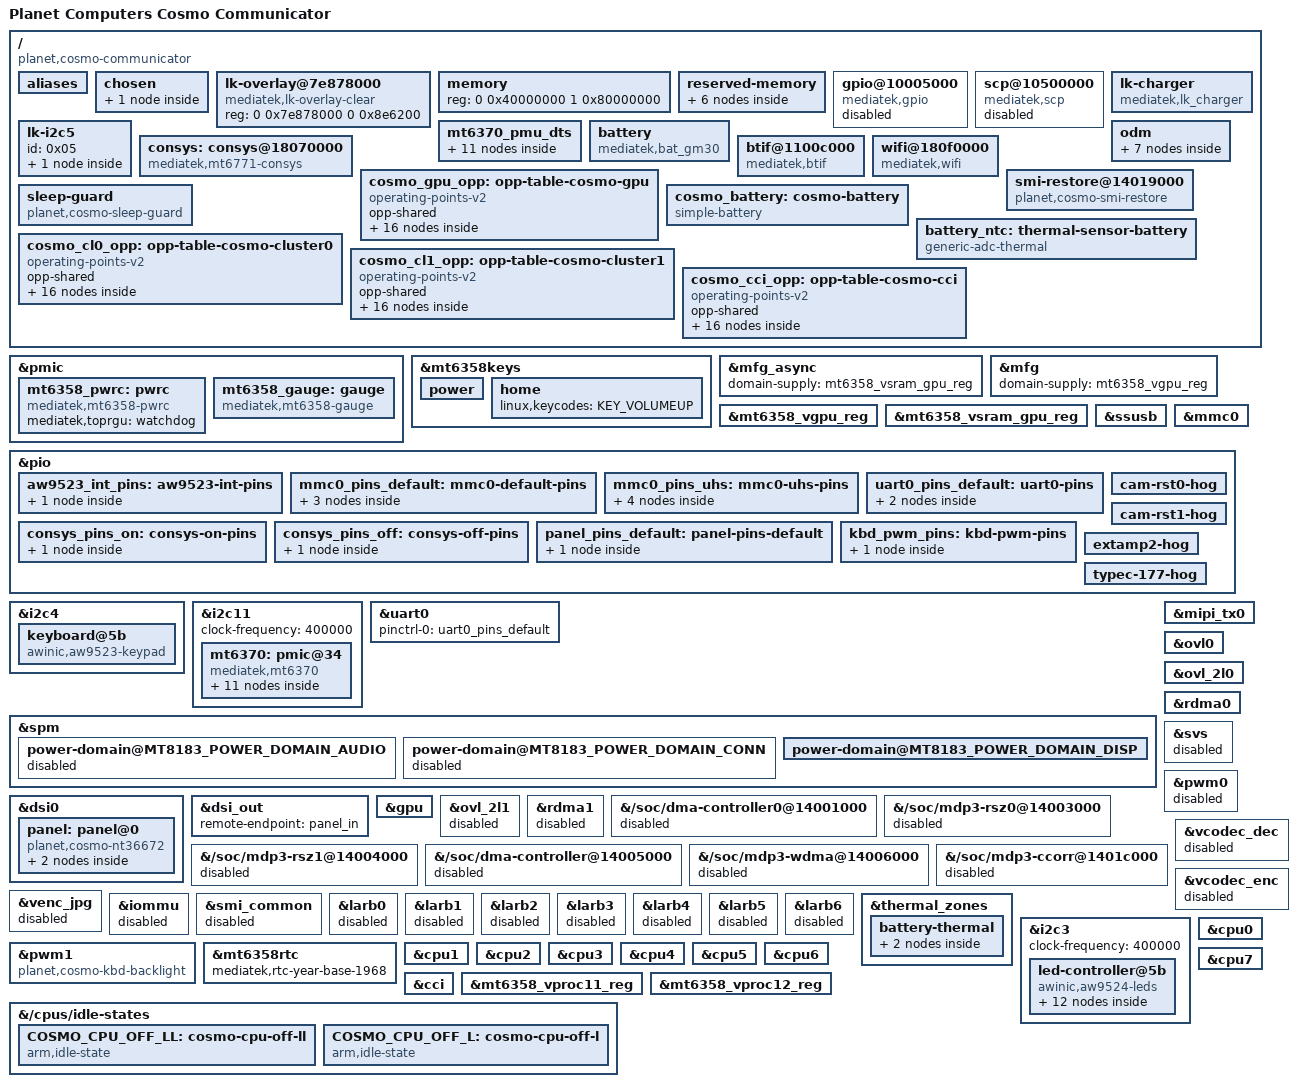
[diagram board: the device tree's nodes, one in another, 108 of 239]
// SPDX-License-Identifier: GPL-2.0-only
/*
 * Planet Computers Cosmo Communicator (MediaTek MT6771 / Helio P70)
 *
 * Phase P1 skeleton: CPUs, GIC, timer, UART0, eMMC, PMIC wrapper + MT6358.
 * Built on mt8183.dtsi: the MT6771 shares the MT8183 register map (97/108
 * mt8183.dtsi nodes at identical addresses), pin table (192 pins, 840
 * functions, 0 differences) and PLL offsets. Receipts: docs/hardware-map.md.
 *
 * Board facts are from gemian/cosmo-linux-kernel-4.4 @ a741a2e8:
 *   arch/arm64/boot/dts/mediatek/mt6771.dts      (base, appended by LK)
 *   arch/arm64/boot/dts/mediatek/k71v1_64_bsp.dts (overlay, odmdtbo)
 *   arch/arm64/boot/dts/mediatek/cust_mt6771_msdc.dtsi
 *
 * Deliberately NOT enabled yet: DSI / display pipeline (LK owns the panel;
 * see AGENTS.md panel rule), GPU, CONSYS, audio, MT6370, Type-C.
 *
 * LK contract (docs/p0-findings.md): LK edits this DTB before handoff. It
 * adds its mblock-* carve-outs (ATF, TEE, SSPM, SPM, SCP, modem, the
 * framebuffer) to /reserved-memory itself, so they are NOT declared here:
 * on the Gemini a duplicate no-map reservation of an LK region hung early
 * boot (gemini-nixos mt6797-gemini-pda.dts, 2026-08-31). The vendor nodes
 * LK looks up by path or compatible are carried below, copied from the
 * stock base DTB + dtbo overlay.
 */

/dts-v1/;
#include <dt-bindings/gpio/gpio.h>
#include <dt-bindings/iio/adc/mediatek,mt6358-auxadc.h>
#include <dt-bindings/iio/adc/mediatek,mt6370_adc.h>
#include <dt-bindings/input/input.h>
#include <dt-bindings/leds/common.h>
#include <dt-bindings/power/mt8183-power.h>
#include "mt8183.dtsi"
#include "mt6358.dtsi"

/ {
	model = "Planet Computers Cosmo Communicator";
	chassis-type = "handset";
	compatible = "planet,cosmo-communicator", "mediatek,mt6771",
		     "mediatek,mt8183";

	aliases {
		serial0 = &uart0;
		mmc0 = &mmc0;
	};

	chosen {
		#address-cells = <2>;
		#size-cells = <2>;
		ranges;

		/* vendor: console=ttyS0,921600n1 (mt6771.dts chosen) */
		stdout-path = "serial0:921600n8";

		/*
		 * LK builds the kernel cmdline on top of this property and
		 * asserts if it is missing ("ASSERT at (app/mt_boot/bootargs.c:96):
		 * fdt_bootargs", LK log 2026-10-25). Vendor value: "console=tty0
		 * console=ttyS0,921600n1 vmalloc=496M slub_max_order=0
		 * slub_debug=OFZPU androidboot.hardware=mt6771
		 * firmware_class.path=/vendor/firmware loop.max_part=7"; only the
		 * consoles are kept. The boot.img cmdline adds the rest.
		 */
		bootargs = "console=tty0 console=ttyS0,921600n1";

		/*
		 * LK's framebuffer = OVL layer 0, scanned out by LK's display
		 * path (no DSI touch: panel rule). Base 0x7df70000 (LK fb_base;
		 * LK reserves 0x7df70000 +0x1f90000 no-map as
		 * mblock-7-framebuffer), 1080x2160, stride 4352 (1088 px).
		 * Format a8r8g8b8 = LK's eBGRA8888 (B,G,R,A in memory): proven on
		 * glass 2026-10-25 by the fbpaint probe (0xffff0000 showed red).
		 * Gemian's fbdev var info (red at bit 0) was wrong.
		 * LK also leaves OVL layer 3 (0x7e878000, pitch 4320) enabled
		 * above it, with the orange-state text drawn on it; /lk-overlay
		 * below clears it. No power-domains: simpledrm then binds as soon as its
		 * driver registers (earliest console); pd_ignore_unused keeps
		 * the display domain on. reg = one buffer (4352 * 2160).
		 */
		framebuffer@7df70000 {
			compatible = "simple-framebuffer";
			reg = <0 0x7df70000 0 0x8f7000>;
			width = <1080>;
			height = <2160>;
			stride = <4352>;
			format = "a8r8g8b8";
		};

	};

	/*
	 * LK's OVL layer 3 buffer: 1080x2160, pitch 4320, inside the no-map
	 * mblock-7-framebuffer reservation. LK draws the orange-state warning
	 * there and leaves the layer enabled above the console framebuffer;
	 * mtk-lk-overlay-clear fills it with transparent pixels at boot.
	 * Memory only, no display register write (panel rule).
	 */
	lk-overlay@7e878000 {
		compatible = "mediatek,lk-overlay-clear";
		reg = <0 0x7e878000 0 0x8e6200>;
	};

	/*
	 * 6 GiB at 0x40000000 (Gemian 4.4 /sys/firmware/fdt, 2026-10-25). LK
	 * looks this node up by the exact path /memory and rewrites it ("DTS:
	 * /memory node is not found create new memory node", and while(1) on
	 * failure, in LK strings), so it is named "memory" like the vendor
	 * node, not memory@40000000 (dtc W=1 warns about that; intended).
	 */
	memory {
		device_type = "memory";
		reg = <0 0x40000000 1 0x80000000>;
	};

	reserved-memory {
		#address-cells = <2>;
		#size-cells = <2>;
		ranges;

		/*
		 * Fixed LK/preloader regions copied from vendor mt6771.dts.
		 * Kept no-map so the kernel never scribbles on them. ATF/TEE/
		 * SSPM regions are expected to be added by LK's fdt fixups at
		 * boot — TODO(P0): confirm from a dump of /proc/device-tree.
		 */
		ram_console@54400000 {
			reg = <0 0x54400000 0 0x10000>;
			no-map;
		};

		/*
		 * ramoops in the vendor pstore region, same layout as Gemian 4.4
		 * (dmesg: console_size 0x40000, pmsg_size 0x10000; record and
		 * ftrace at the 4.4 defaults of 4 KiB). The other kernel can then
		 * read this kernel's console log after a reboot.
		 */
		ramoops@54410000 {
			compatible = "ramoops";
			reg = <0 0x54410000 0 0xe0000>;
			record-size = <0x1000>;
			console-size = <0x40000>;
			ftrace-size = <0x1000>;
			pmsg-size = <0x10000>;
		};

		minirdump@544f0000 {
			reg = <0 0x544f0000 0 0x10000>;
			no-map;
		};

		/*
		 * Required by mt8183.dtsi's &scp, and LK looks it up by the
		 * vendor name/compatible: one pool for both. Sized exactly as
		 * vendor reserve-memory-scp_share (20 MiB, 16 MiB aligned).
		 * SCP itself stays disabled until P2.
		 */
		scp_mem_reserved: reserve-memory-scp_share {
			compatible = "shared-dma-pool",
				     "mediatek,reserve-memory-scp_share";
			size = <0 0x1400000>;
			alignment = <0 0x1000000>;
			alloc-ranges = <0 0x40000000 0 0x50000000>;
			no-map;
		};

		/* LK reads /reserved-memory/reserve-memory-sspm_share (LK strings); vendor node verbatim */
		reserve-memory-sspm_share {
			compatible = "mediatek,reserve-memory-sspm_share";
			no-map;
			size = <0 0x510000>;
			alignment = <0 0x10000>;
			alloc-ranges = <0 0x40000000 0 0x60000000>;
		};

		/*
		 * CONSYS (Wi-Fi/BT MCU) shared memory, vendor mt6771.dts node
		 * verbatim. Dynamic: the driver programs the chosen base into
		 * the CONSYS EMI remap (docs/wifi-stock.md).
		 */
		consys_mem: consys-reserve-memory {
			compatible = "mediatek,consys-reserve-memory";
			no-map;
			size = <0 0x200000>;
			alignment = <0 0x200000>;
			alloc-ranges = <0 0x40000000 0 0x80000000>;
		};
	};

	/*
	 * Vendor nodes LK reads before handoff, verbatim from the stock base
	 * DTB + dtbo overlay (fdtoverlay, 2026-10-25); phandles dropped. No
	 * mainline driver matches these compatibles; status disabled keeps
	 * Linux from creating devices for them.
	 *  - /gpio@10005000: LK applies gpio_init_default (stock pin setup)
	 *    by path ("[GPIO] Found /gpio@10005000" in the LK log).
	 *  - mediatek,scp: LK's platform_fdt_scp() ("[SCP] mediatek,scp not
	 *    found!"); on the Gemini a missing scp node asserted in LK.
	 *  - mediatek,lk_charger: LK charger limits.
	 */
	gpio@10005000 {
		gpio_init_default = <0x00 0x07 0x01 0x00 0x00 0x00 0x01 0x01 0x07 0x01 0x00 0x01 0x00 0x01 0x02 0x07 0x01 0x00 0x00 0x00 0x01 0x03 0x00 0x00 0x00 0x01 0x01 0x01 0x04 0x00 0x00 0x00 0x01 0x01 0x00 0x05 0x00 0x00 0x00 0x01 0x00 0x00 0x06 0x00 0x00 0x00 0x01 0x01 0x00 0x07 0x00 0x00 0x00 0x01 0x00 0x00 0x08 0x00 0x00 0x00 0x01 0x01 0x00 0x09 0x00 0x00 0x00 0x01 0x01 0x00 0x0a 0x00 0x00 0x00 0x01 0x01 0x00 0x0b 0x00 0x00 0x00 0x01 0x01 0x00 0x0c 0x00 0x00 0x00 0x01 0x01 0x00 0x0d 0x01 0x01 0x00 0x00 0x00 0x00 0x0e 0x01 0x01 0x00 0x00 0x00 0x00 0x0f 0x01 0x01 0x00 0x00 0x00 0x00 0x10 0x01 0x01 0x00 0x00 0x00 0x00 0x11 0x01 0x01 0x00 0x00 0x00 0x00 0x12 0x01 0x01 0x00 0x00 0x00 0x00 0x13 0x01 0x01 0x00 0x00 0x00 0x00 0x14 0x01 0x01 0x00 0x00 0x00 0x00 0x15 0x01 0x01 0x00 0x00 0x00 0x00 0x16 0x01 0x01 0x00 0x00 0x00 0x00 0x17 0x01 0x01 0x00 0x00 0x00 0x00 0x18 0x01 0x01 0x00 0x00 0x00 0x00 0x19 0x01 0x01 0x00 0x00 0x00 0x00 0x1a 0x01 0x01 0x00 0x00 0x00 0x00 0x1b 0x01 0x01 0x00 0x00 0x00 0x00 0x1c 0x01 0x01 0x00 0x00 0x00 0x00 0x1d 0x01 0x01 0x00 0x00 0x00 0x00 0x1e 0x01 0x00 0x00 0x01 0x01 0x00 0x1f 0x01 0x00 0x00 0x01 0x01 0x00 0x20 0x01 0x00 0x00 0x01 0x01 0x00 0x21 0x01 0x00 0x00 0x01 0x01 0x00 0x22 0x01 0x00 0x00 0x01 0x01 0x00 0x23 0x01 0x00 0x00 0x01 0x01 0x00 0x24 0x01 0x01 0x00 0x00 0x00 0x00 0x25 0x01 0x01 0x00 0x00 0x00 0x00 0x26 0x01 0x01 0x00 0x00 0x00 0x00 0x27 0x01 0x01 0x00 0x00 0x00 0x00 0x28 0x01 0x00 0x00 0x01 0x01 0x00 0x29 0x00 0x00 0x00 0x01 0x01 0x00 0x2a 0x00 0x01 0x00 0x00 0x00 0x00 0x2b 0x01 0x01 0x00 0x00 0x00 0x00 0x2c 0x01 0x00 0x00 0x01 0x00 0x00 0x2d 0x01 0x01 0x01 0x00 0x00 0x00 0x2e 0x00 0x00 0x00 0x01 0x00 0x00 0x2f 0x01 0x00 0x00 0x01 0x01 0x00 0x30 0x01 0x00 0x00 0x01 0x01 0x00 0x31 0x01 0x00 0x00 0x01 0x01 0x00 0x32 0x01 0x00 0x00 0x01 0x01 0x00 0x33 0x01 0x00 0x00 0x01 0x01 0x00 0x34 0x00 0x01 0x00 0x01 0x00 0x00 0x35 0x00 0x01 0x00 0x01 0x00 0x00 0x36 0x00 0x00 0x00 0x01 0x00 0x00 0x37 0x01 0x01 0x00 0x01 0x00 0x00 0x38 0x01 0x01 0x00 0x01 0x00 0x00 0x39 0x01 0x01 0x00 0x01 0x00 0x00 0x3a 0x00 0x00 0x00 0x01 0x00 0x00 0x3b 0x01 0x00 0x00 0x01 0x00 0x00 0x3c 0x01 0x00 0x00 0x01 0x00 0x00 0x3d 0x01 0x00 0x00 0x01 0x00 0x00 0x3e 0x01 0x00 0x00 0x01 0x00 0x00 0x3f 0x01 0x00 0x00 0x01 0x00 0x00 0x40 0x01 0x00 0x00 0x01 0x00 0x00 0x41 0x00 0x00 0x00 0x01 0x00 0x00 0x42 0x00 0x00 0x00 0x01 0x00 0x00 0x43 0x01 0x00 0x00 0x01 0x00 0x00 0x44 0x01 0x00 0x00 0x01 0x00 0x00 0x45 0x00 0x00 0x00 0x01 0x00 0x00 0x46 0x00 0x01 0x00 0x01 0x00 0x00 0x47 0x00 0x00 0x00 0x01 0x00 0x00 0x48 0x00 0x01 0x00 0x01 0x00 0x00 0x49 0x00 0x01 0x00 0x01 0x00 0x00 0x4a 0x00 0x01 0x00 0x01 0x00 0x00 0x4b 0x00 0x01 0x00 0x01 0x00 0x00 0x4c 0x00 0x01 0x01 0x01 0x00 0x00 0x4d 0x00 0x01 0x00 0x01 0x00 0x00 0x4e 0x00 0x00 0x00 0x01 0x01 0x00 0x4f 0x00 0x00 0x00 0x01 0x00 0x00 0x50 0x00 0x00 0x00 0x01 0x00 0x00 0x51 0x01 0x00 0x00 0x01 0x01 0x00 0x52 0x01 0x00 0x00 0x01 0x01 0x00 0x53 0x01 0x00 0x00 0x01 0x01 0x00 0x54 0x01 0x00 0x00 0x01 0x01 0x00 0x55 0x01 0x01 0x00 0x00 0x00 0x00 0x56 0x01 0x00 0x00 0x01 0x00 0x00 0x57 0x01 0x00 0x00 0x01 0x00 0x00 0x58 0x01 0x00 0x00 0x01 0x00 0x00 0x59 0x01 0x00 0x00 0x01 0x00 0x00 0x5a 0x01 0x01 0x00 0x00 0x00 0x00 0x5b 0x00 0x01 0x00 0x00 0x00 0x00 0x5c 0x00 0x01 0x00 0x00 0x00 0x00 0x5d 0x00 0x01 0x00 0x01 0x01 0x00 0x5e 0x07 0x00 0x00 0x01 0x00 0x00 0x5f 0x01 0x01 0x00 0x00 0x00 0x00 0x60 0x01 0x01 0x00 0x00 0x00 0x00 0x61 0x00 0x01 0x00 0x00 0x00 0x00 0x62 0x00 0x01 0x00 0x00 0x00 0x00 0x63 0x00 0x01 0x00 0x00 0x00 0x00 0x64 0x00 0x01 0x00 0x00 0x00 0x00 0x65 0x00 0x01 0x01 0x00 0x00 0x00 0x66 0x00 0x01 0x01 0x00 0x00 0x00 0x67 0x01 0x00 0x00 0x01 0x01 0x00 0x68 0x01 0x00 0x00 0x01 0x01 0x00 0x69 0x01 0x00 0x00 0x01 0x01 0x00 0x6a 0x01 0x00 0x00 0x01 0x01 0x00 0x6b 0x00 0x01 0x01 0x00 0x00 0x00 0x6c 0x00 0x01 0x00 0x00 0x00 0x00 0x6d 0x00 0x01 0x00 0x00 0x00 0x00 0x6e 0x07 0x00 0x00 0x01 0x01 0x00 0x6f 0x00 0x00 0x00 0x00 0x00 0x01 0x70 0x07 0x01 0x00 0x00 0x00 0x00 0x71 0x01 0x00 0x00 0x01 0x00 0x00 0x72 0x01 0x00 0x00 0x01 0x00 0x00 0x73 0x01 0x00 0x00 0x01 0x00 0x00 0x74 0x01 0x00 0x00 0x01 0x00 0x00 0x75 0x01 0x00 0x00 0x01 0x00 0x00 0x76 0x01 0x00 0x00 0x01 0x00 0x00 0x77 0x01 0x00 0x00 0x01 0x00 0x00 0x78 0x01 0x00 0x00 0x01 0x00 0x00 0x79 0x01 0x00 0x00 0x01 0x00 0x00 0x7a 0x01 0x00 0x00 0x01 0x01 0x00 0x7b 0x01 0x00 0x00 0x01 0x01 0x00 0x7c 0x01 0x01 0x00 0x00 0x00 0x00 0x7d 0x01 0x00 0x00 0x01 0x01 0x00 0x7e 0x01 0x00 0x00 0x01 0x01 0x00 0x7f 0x01 0x00 0x00 0x01 0x01 0x00 0x80 0x01 0x00 0x00 0x01 0x01 0x00 0x81 0x01 0x00 0x00 0x01 0x01 0x00 0x82 0x01 0x00 0x00 0x01 0x01 0x00 0x83 0x01 0x00 0x00 0x01 0x00 0x00 0x84 0x01 0x00 0x00 0x01 0x01 0x00 0x85 0x01 0x01 0x01 0x00 0x00 0x00 0x86 0x01 0x00 0x00 0x01 0x00 0x01 0x87 0x01 0x01 0x00 0x00 0x00 0x00 0x88 0x01 0x01 0x00 0x01 0x00 0x00 0x89 0x01 0x01 0x00 0x01 0x00 0x00 0x8a 0x01 0x01 0x00 0x00 0x00 0x00 0x8b 0x01 0x01 0x00 0x01 0x00 0x00 0x8c 0x01 0x00 0x00 0x00 0x00 0x00 0x8d 0x01 0x00 0x00 0x00 0x00 0x00 0x8e 0x01 0x00 0x00 0x00 0x00 0x00 0x8f 0x01 0x00 0x00 0x00 0x00 0x00 0x90 0x01 0x00 0x00 0x01 0x00 0x00 0x91 0x01 0x01 0x01 0x00 0x00 0x00 0x92 0x01 0x00 0x00 0x01 0x00 0x00 0x93 0x01 0x01 0x00 0x00 0x00 0x00 0x94 0x01 0x01 0x00 0x00 0x00 0x00 0x95 0x01 0x01 0x00 0x00 0x00 0x00 0x96 0x00 0x01 0x00 0x00 0x00 0x00 0x97 0x00 0x01 0x00 0x00 0x00 0x00 0x98 0x00 0x01 0x00 0x00 0x00 0x00 0x99 0x00 0x01 0x00 0x00 0x00 0x00 0x9a 0x01 0x01 0x00 0x00 0x00 0x00 0x9b 0x01 0x00 0x00 0x01 0x00 0x00 0x9c 0x00 0x01 0x01 0x01 0x00 0x00 0x9d 0x00 0x00 0x00 0x01 0x00 0x00 0x9e 0x00 0x01 0x01 0x00 0x00 0x00 0x9f 0x00 0x01 0x00 0x00 0x00 0x00 0xa0 0x00 0x01 0x01 0x01 0x01 0x00 0xa1 0x02 0x00 0x00 0x00 0x00 0x00 0xa2 0x02 0x01 0x00 0x00 0x00 0x00 0xa3 0x02 0x01 0x00 0x00 0x00 0x00 0xa4 0x02 0x01 0x00 0x00 0x00 0x00 0xa5 0x02 0x01 0x00 0x00 0x00 0x00 0xa6 0x00 0x00 0x00 0x01 0x01 0x00 0xa7 0x01 0x01 0x00 0x01 0x00 0x00 0xa8 0x01 0x01 0x00 0x01 0x00 0x00 0xa9 0x02 0x01 0x00 0x00 0x00 0x00 0xaa 0x02 0x01 0x00 0x00 0x00 0x00 0xab 0x02 0x01 0x00 0x00 0x00 0x00 0xac 0x02 0x01 0x00 0x00 0x00 0x00 0xad 0x02 0x01 0x00 0x00 0x00 0x00 0xae 0x02 0x01 0x00 0x00 0x00 0x00 0xaf 0x00 0x01 0x00 0x00 0x00 0x00 0xb0 0x00 0x01 0x00 0x00 0x00 0x00 0xb1 0x00 0x01 0x00 0x00 0x00 0x00 0xb2 0x00 0x00 0x00 0x01 0x00 0x00 0xb3 0x00 0x00 0x00 0x01 0x00 0x00 0xb4 0x00 0x00 0x00 0x01 0x00 0x00 0xb5 0x00 0x00 0x00 0x01 0x00 0x00 0xb6 0x00 0x00 0x00 0x01 0x00 0x00 0xb7 0x00 0x00 0x00 0x01 0x00 0x00 0xb8 0x00 0x00 0x00 0x01 0x00 0x00 0xb9 0x00 0x00 0x00 0x01 0x00 0x00 0xba 0x00 0x00 0x00 0x01 0x00 0x00 0xbb 0x00 0x00 0x00 0x01 0x00 0x00 0xbc 0x00 0x00 0x00 0x01 0x00 0x00 0xbd 0x00 0x00 0x00 0x01 0x00 0x00 0xbe 0x00 0x00 0x00 0x01 0x00 0x00 0xbf 0x00 0x00 0x00 0x01 0x00 0x00>;
		compatible = "mediatek,gpio";
		reg = <0x00 0x10005000 0x00 0x1000>;
		status = "disabled";
	};

	scp@10500000 {
		scp_sramSize = <0x80000>;
		core_1 = "enable";
		compatible = "mediatek,scp";
		status = "disabled";
		reg = <0x00 0x10500000 0x00 0x80000 0x00 0x105c0000 0x00 0x3000 0x00 0x105c4000 0x00 0x1000 0x00 0x105d4000 0x00 0x6000>;
		interrupts = <0x00 0xae 0x04>;
	};

	lk-charger {
		compatible = "mediatek,lk_charger";
		enable_pe_plus;
		power_path_support;
		max_charger_voltage = <0x632ea0>;
		fast_charge_voltage = <0x2dc6c0>;
		usb_charger_current = <0x7a120>;
		ac_charger_current = <0x1f47d0>;
		ac_charger_input_current = <0x30d400>;
		non_std_ac_charger_current = <0x1f47d0>;
		charging_host_charger_current = <0x16e360>;
		ta_ac_charger_current = <0x2dc6c0>;
		pd_charger_current = <0x7a120>;
		temp_t4_threshold = <0x32>;
		temp_t3_threshold = <0x2d>;
		temp_t1_threshold = <0x00>;
	};

	/*
	 * More vendor data LK reads on a stock boot (Gemian pl_lk log,
	 * 2026-10-25), verbatim from the stock base DTB + overlay, phandles
	 * dropped. None has a compatible Linux binds (no compatible at all on
	 * the parents), so Linux creates no devices from them.
	 *  - subpmic_pmu: LK's MT6370 drivers ("mt6370_parse_dt: subpmic_pmu
	 *    id = 5") find it by compatible and take the bus id from the
	 *    parent. Vendor parent: i2c5 @ 0x11017000, which is mainline
	 *    &i2c11 (mainline i2c5 is 0x11016000).
	 *  - mt6370_pmu_dts: LK backlight (bled) and charger settings.
	 *    mt6370,intr_gpio held a raw vendor phandle to its pio; written
	 *    as &pio.
	 *  - battery (mediatek,bat_gm30): LK gauge ("init_bat_cust_data_dt").
	 *  - /odm/led@0-6: LK LED init; led@6 is the LCD backlight ("[LEDS]LK:
	 *    led[6] … mode is 5"). Without it LK may leave the backlight off.
	 */
	lk-i2c5 {
		#address-cells = <1>;
		#size-cells = <0>;
		id = <0x05>;

		subpmic_pmu@34 {
			status = "okay";
			reg = <0x34>;
			compatible = "mediatek,subpmic_pmu";
		};
	};

	mt6370_pmu_dts {
		interrupt-controller;
		#interrupt-cells = <0x01>;
		mt6370,intr_gpio_num = <0x0a>;
		mt6370,intr_gpio = <&pio 0x0a 0x00>;

		core {
			compatible = "mediatek,mt6370_pmu_core";
			interrupt-names = "otp", "vdda_ovp", "vdda_uv";
			i2cstmr_rst_tmr = <0x00>;
			mrstb_en;
			mrstb_tmr = <0x03>;
			int_wdt = <0x00>;
			int_deg = <0x00>;
		};

		charger {
			compatible = "mediatek,mt6370_pmu_charger";
			interrupt-names = "chg_mivr", "chg_aiclmeasi", "attachi", "ovpctrl_uvp_d_evt", "chg_wdtmri", "chg_vbusov", "chg_tmri", "chg_treg", "dcdti";
			charger_name = "primary_chg";
			load_switch_name = "primary_load_switch";
			ichg = <0x1f47d0>;
			aicr = <0x30d400>;
			mivr = <0x432380>;
			cv = <0x432380>;
			ieoc = <0x249f0>;
			safety_timer = <0x0c>;
			dc_wdt = "", "=\t";
			ircmp_resistor = <0x61a8>;
			ircmp_vclamp = <0x7d00>;
			enable_te;
			enable_wdt;
			lbp_hys_sel = <0x01>;
			lbp_dt = <0x01>;
		};

		mt6370_pmu_fled1 {
			compatible = "mediatek,mt6370_pmu_fled1";
			interrupt-names = "fled_lvf", "fled2_short", "fled1_short";
			fled_enable = <0x01>;
			torch_cur = <0x493e0>;
			strobe_cur = <0x124f80>;
			strobe_timeout = <0x960>;
		};

		mt6370_pmu_fled2 {
			compatible = "mediatek,mt6370_pmu_fled2";
			fled_enable = <0x01>;
			torch_cur = <0x30d40>;
			strobe_cur = <0xf4240>;
			strobe_timeout = <0x4b0>;
		};

		ldo {
			compatible = "mediatek,mt6370_pmu_ldo";
			interrupt-names = "ldo_oc";
			ldo_oms = <0x01>;
			ldo_vrc_lt = <0x01>;

			mt6370_ldo {
				regulator-name = "irtx_ldo";
				regulator-min-microvolt = <0x186a00>;
				regulator-max-microvolt = "", "=\t";
			};
		};

		rgbled {
			compatible = "mediatek,mt6370_pmu_rgbled";
			interrupt-names = "isink4_short", "isink3_short", "isink2_short", "isink1_short", "isink4_open", "isink3_open", "isink2_open", "isink1_open";
			mt,led_name = "green", "blue", "mt6370_pmu_led3", "red";
			mt,led_default_trigger = "cc_mode", "cc_mode", "cc_mode", "cc_mode";
		};

		bled {
			compatible = "mediatek,mt6370_pmu_bled";
			interrupt-names = "bled_ocp";
			mt,bled_name = "mt6370_pmu_bled";
			mt,chan_en = <0x0f>;
			mt,map_linear;
			mt,bl_ovp_level = <0x03>;
			mt,bl_ocp_level = <0x02>;
			mt,use_pwm;
			mt,pwm_fsample = <0x02>;
			mt,pwm_deglitch = <0x01>;
			mt,pwm_hys_en = <0x01>;
			mt,pwm_hys = <0x00>;
			mt,pwm_avg_cycle = <0x00>;
			mt,bled_ramptime = <0x03>;
			mt,bled_flash_ramp = <0x01>;
			mt,max_bled_brightness = <0x300>;
			mt,bled_curr_scale = <0x00>;
			mt,pwm_lpf_coef = <0x00>;
		};

		dsv {
			compatible = "mediatek,mt6370_pmu_dsv";
			interrupt-names = "dsv_vneg_ocp", "dsv_vpos_ocp", "dsv_bst_ocp", "dsv_vneg_scp", "dsv_vpos_scp";
			db_ext_en = <0x00>;
			db_periodic_fix = <0x00>;
			db_single_pin = <0x00>;
			db_freq_pm = <0x00>;
			db_periodic_mode = <0x00>;
			db_startup = <0x00>;
			db_vneg_20ms = <0x01>;
			db_vneg_disc = <0x00>;
			db_vpos_20ms = <0x01>;
			db_vpos_disc = <0x01>;
			db_delay = <0x03>;
			db_vbst = <0x1644>;
			db_vpos_slew = <0x01>;
			db_vneg_slew = <0x01>;

			mt6370_dsvp {
				regulator-name = "dsv_pos";
				regulator-min-microvolt = "", "=\t";
				regulator-max-microvolt = <0x5b8d80>;
			};

			mt6370_dsvn {
				regulator-name = "dsv_neg";
				regulator-min-microvolt = "", "=\t";
				regulator-max-microvolt = <0x5b8d80>;
			};
		};
	};

	battery {
		compatible = "mediatek,bat_gm30";
		DIFFERENCE_FULLOCV_ITH = <0x12c>;
		SHUTDOWN_1_TIME = <0x1e>;
		KEEP_100_PERCENT = <0x01>;
		R_FG_VALUE = <0x0a>;
		EMBEDDED_SEL = <0x00>;
		PMIC_SHUTDOWN_CURRENT = <0x14>;
		FG_METER_RESISTANCE = <0x32>;
		CAR_TUNE_VALUE = <0x5d>;
		PMIC_MIN_VOL = <0x84d0>;
		POWERON_SYSTEM_IBOOT = <0x1f4>;
		SHUTDOWN_GAUGE0_VOLTAGE = <0x84d0>;
		TEMPERATURE_T0 = <0x32>;
		TEMPERATURE_T1 = <0x19>;
		TEMPERATURE_T2 = <0x00>;
		TEMPERATURE_T3 = <0xfffffff6>;
		g_FG_PSEUDO100_T0 = <0x62>;
		g_FG_PSEUDO100_T1 = <0x62>;
		g_FG_PSEUDO100_T2 = <0x5a>;
		g_FG_PSEUDO100_T3 = <0x50>;
		Q_MAX_SYS_VOLTAGE_BAT0 = <0xd48>;
		Q_MAX_SYS_VOLTAGE_BAT1 = <0xd48>;
		Q_MAX_SYS_VOLTAGE_BAT2 = <0xd48>;
		Q_MAX_SYS_VOLTAGE_BAT3 = <0xd48>;
		battery0_profile_t0_num = <0x64>;
		battery0_profile_t0 = <0x00 0xa8f9 0x442 0x1ba 0xa87d 0x440 0x374 0xa806 0x44b 0x52e 0xa78e 0x44e 0x6e8 0xa717 0x44e 0x8a2 0xa69f 0x44f 0xa5c 0xa627 0x451 0xc16 0xa5ae 0x454 0xdcf 0xa538 0x44f 0xf89 0xa4c3 0x458 0x1143 0xa44c 0x450 0x12fd 0xa3d8 0x454 0x14b7 0xa363 0x456 0x1671 0xa2f1 0x457 0x182b 0xa280 0x45f 0x19e5 0xa20e 0x465 0x1b9f 0xa19b 0x45f 0x1d59 0xa12d 0x465 0x1f13 0xa0bc 0x465 0x20cd 0xa051 0x465 0x2287 0x9fe3 0x46a 0x2441 0x9f7b 0x473 0x25fa 0x9f13 0x477 0x27b4 0x9ea8 0x479 0x296e 0x9e42 0x47f 0x2b28 0x9de2 0x486 0x2ce2 0x9d81 0x494 0x2e9c 0x9d13 0x495 0x3056 0x9ca7 0x4a7 0x3210 0x9c58 0x4c0 0x33ca 0x9c04 0x4c6 0x3584 0x9bac 0x4cf 0x373e 0x9b57 0x4e6 0x38f8 0x9b01 0x4fd 0x3ab2 0x9aa6 0x50d 0x3c6c 0x9a44 0x51f 0x3e25 0x99cc 0x4fe 0x3fdf 0x9937 0x4b5 0x4199 0x98b1 0x474 0x4353 0x9847 0x45e 0x450d 0x97f1 0x457 0x46c7 0x97a3 0x44f 0x4881 0x975b 0x44f 0x4a3b 0x971a 0x44f 0x4bf5 0x96de 0x44e 0x4daf 0x969e 0x44f 0x4f69 0x9666 0x44f 0x5123 0x962f 0x44f 0x52dd 0x95f8 0x44f 0x5497 0x95c6 0x452 0x5650 0x9597 0x456 0x580a 0x9568 0x458 0x59c4 0x953a 0x45e 0x5b7e 0x950e 0x467 0x5d38 0x94e4 0x46c 0x5ef2 0x94be 0x474 0x60ac 0x9497 0x475 0x6266 0x9473 0x47d 0x6420 0x9450 0x486 0x65da 0x942d 0x48c 0x6794 0x940e 0x49c 0x694e 0x93ed 0x49f 0x6b08 0x93ce 0x4ab 0x6cc2 0x93ab 0x4ab 0x6e7b 0x9377 0x495 0x7035 0x932f 0x46f 0x71ef 0x92e4 0x45f 0x73a9 0x92a7 0x463 0x7563 0x9278 0x469 0x771d 0x924d 0x46c 0x78d7 0x921f 0x467 0x7a91 0x91f3 0x465 0x7c4b 0x91c4 0x45f 0x7e05 0x919f 0x463 0x7fbf 0x917b 0x466 0x8179 0x9154 0x46a 0x8333 0x9124 0x46a 0x84ed 0x90e7 0x466 0x86a6 0x90a6 0x469 0x8860 0x9071 0x46f 0x8a1a 0x902f 0x46d 0x8bd4 0x8fdc 0x461 0x8d8e 0x8fb3 0x45e 0x8f48 0x8fa2 0x463 0x9102 0x8f98 0x471 0x92bc 0x8f8e 0x481 0x9476 0x8f7e 0x494 0x9630 0x8f5e 0x4ad 0x97ea 0x8f11 0x4ba 0x99a4 0x8de7 0x499 0x9b5e 0x8c1f 0x4a8 0x9d18 0x89c2 0x4d0 0x9ed1 0x8671 0x524 0xa08b 0x80bf 0x732 0xa245 0x7bbd 0x9ab 0xa3ff 0x7bbd 0x9ab 0xa5b9 0x7bbd 0x9ab 0xa773 0x7bbd 0x9ab 0xa92d 0x7bbd 0x9ab 0xaae7 0x7bbd 0x9ab>;
		battery0_profile_t1_num = <0x64>;
		battery0_profile_t1 = <0x00 0xaa7f 0x794 0x1ba 0xaa14 0x794 0x374 0xa9a2 0x788 0x52e 0xa929 0x771 0x6e8 0xa8ae 0x756 0x8a2 0xa831 0x73f 0xa5c 0xa7b4 0x731 0xc16 0xa73a 0x727 0xdcf 0xa6c5 0x720 0xf89 0xa655 0x71a 0x1143 0xa5e1 0x6fe 0x12fd 0xa56a 0x72c 0x14b7 0xa4f7 0x74d 0x1671 0xa483 0x74d 0x182b 0xa40e 0x73c 0x19e5 0xa39c 0x730 0x1b9f 0xa32c 0x738 0x1d59 0xa2bc 0x738 0x1f13 0xa24b 0x73e 0x20cd 0xa1db 0x739 0x2287 0xa16b 0x72d 0x2441 0xa0fb 0x735 0x25fa 0xa089 0x73b 0x27b4 0xa017 0x737 0x296e 0x9fab 0x742 0x2b28 0x9f45 0x755 0x2ce2 0x9eed 0x73d 0x2e9c 0x9eb5 0x779 0x3056 0x9e67 0x790 0x3210 0x9de8 0x76d 0x33ca 0x9d41 0x739 0x3584 0x9c96 0x71f 0x373e 0x9c06 0x725 0x38f8 0x9b95 0x730 0x3ab2 0x9b3c 0x740 0x3c6c 0x9afb 0x74d 0x3e25 0x9acb 0x781 0x3fdf 0x9a98 0x7a7 0x4199 0x9a48 0x78f 0x4353 0x99df 0x74d 0x450d 0x996a 0x6fe 0x46c7 0x98f2 0x6ae 0x4881 0x987c 0x669 0x4a3b 0x9813 0x638 0x4bf5 0x97bf 0x60e 0x4daf 0x9771 0x5f2 0x4f69 0x972a 0x5f3 0x5123 0x96e9 0x601 0x52dd 0x96ab 0x603 0x5497 0x9671 0x5ff 0x5650 0x963b 0x60a 0x580a 0x9606 0x610 0x59c4 0x95d2 0x609 0x5b7e 0x95a1 0x609 0x5d38 0x9574 0x614 0x5ef2 0x9548 0x618 0x60ac 0x951c 0x60f 0x6266 0x94f3 0x60d 0x6420 0x94cd 0x618 0x65da 0x94a7 0x61b 0x6794 0x9486 0x62f 0x694e 0x9462 0x62f 0x6b08 0x943f 0x611 0x6cc2 0x9420 0x618 0x6e7b 0x9402 0x625 0x7035 0x93e5 0x62d 0x71ef 0x93c9 0x634 0x73a9 0x93aa 0x63a 0x7563 0x938b 0x63c 0x771d 0x9365 0x62f 0x78d7 0x933c 0x614 0x7a91 0x9319 0x60b 0x7c4b 0x92f6 0x609 0x7e05 0x92d0 0x601 0x7fbf 0x92a8 0x5fd 0x8179 0x9282 0x604 0x8333 0x925c 0x609 0x84ed 0x9238 0x607 0x86a6 0x9214 0x609 0x8860 0x91e9 0x5fb 0x8a1a 0x91b7 0x5f9 0x8bd4 0x917d 0x5fd 0x8d8e 0x9143 0x60e 0x8f48 0x910c 0x62d 0x9102 0x90cd 0x649 0x92bc 0x9080 0x652 0x9476 0x9035 0x648 0x9630 0x9021 0x64e 0x97ea 0x9013 0x661 0x99a4 0x9007 0x685 0x9b5e 0x8ff9 0x6b2 0x9d18 0x8fe1 0x6f1 0x9ed1 0x8fa5 0x73a 0xa08b 0x8ef8 0x75f 0xa245 0x8d74 0x74e 0xa3ff 0x8b53 0x799 0xa5b9 0x8853 0x819 0xa773 0x83ac 0x908 0xa92d 0x793c 0x3994 0xaae7 0x73b6 0x5762>;
		battery0_profile_t2_num = <0x64>;
		battery0_profile_t2 = <0x00 0xaa8f 0x1de2 0x1ba 0xa9d5 0x1de2 0x374 0xa92c 0x1f86 0x52e 0xa889 0x1fe0 0x6e8 0xa7ee 0x1fa5 0x8a2 0xa75b 0x1f34 0xa5c 0xa6d0 0x1eda 0xc16 0xa64b 0x1f06 0xdcf 0xa5ce 0x1ece 0xf89 0xa550 0x1e89 0x1143 0xa4d7 0x1e60 0x12fd 0xa461 0x1e1a 0x14b7 0xa3ed 0x1dce 0x1671 0xa379 0x1d92 0x182b 0xa305 0x1d61 0x19e5 0xa294 0x1d29 0x1b9f 0xa21e 0x1cf1 0x1d59 0xa1ab 0x1cb4 0x1f13 0xa138 0x1c7c 0x20cd 0xa0c8 0x1c47 0x2287 0xa063 0x1c2e 0x2441 0xa005 0x1c1c 0x25fa 0x9fac 0x1c11 0x27b4 0x9f54 0x1c07 0x296e 0x9ef2 0x1be4 0x2b28 0x9e7b 0x1ba2 0x2ce2 0x9de7 0x1b29 0x2e9c 0x9d3a 0x1a86 0x3056 0x9c8f 0x19e8 0x3210 0x9bf3 0x1963 0x33ca 0x9b69 0x18fe 0x3584 0x9af1 0x18ab 0x373e 0x9a85 0x1862 0x38f8 0x9a26 0x1831 0x3ab2 0x99cf 0x1801 0x3c6c 0x9982 0x17d9 0x3e25 0x9933 0x17aa 0x3fdf 0x98e8 0x177b 0x4199 0x989d 0x1747 0x4353 0x984f 0x170d 0x450d 0x9802 0x16d8 0x46c7 0x97ba 0x16b3 0x4881 0x976f 0x1686 0x4a3b 0x972c 0x1669 0x4bf5 0x96eb 0x165b 0x4daf 0x96ab 0x1646 0x4f69 0x966e 0x1632 0x5123 0x9635 0x162c 0x52dd 0x95ff 0x1633 0x5497 0x95cc 0x1638 0x5650 0x959b 0x163d 0x580a 0x956a 0x1651 0x59c4 0x953b 0x1651 0x5b7e 0x950f 0x1656 0x5d38 0x94e7 0x1662 0x5ef2 0x94c1 0x1678 0x60ac 0x949b 0x168a 0x6266 0x9476 0x1699 0x6420 0x9456 0x16b9 0x65da 0x9438 0x16d2 0x6794 0x941f 0x1707 0x694e 0x9409 0x173e 0x6b08 0x93f6 0x177a 0x6cc2 0x93e3 0x17bd 0x6e7b 0x93d1 0x1808 0x7035 0x93bf 0x1855 0x71ef 0x93ac 0x189b 0x73a9 0x9397 0x18e2 0x7563 0x9386 0x194a 0x771d 0x9370 0x1992 0x78d7 0x935a 0x19ed 0x7a91 0x9345 0x1a50 0x7c4b 0x932d 0x1ab1 0x7e05 0x9312 0x1b17 0x7fbf 0x92f3 0x1b88 0x8179 0x92d1 0x1bfc 0x8333 0x92ad 0x1c72 0x84ed 0x9287 0x1d08 0x86a6 0x925b 0x1d91 0x8860 0x922d 0x1e2a 0x8a1a 0x91f7 0x1ed5 0x8bd4 0x91bf 0x1f8f 0x8d8e 0x9186 0x205a 0x8f48 0x914a 0x213e 0x9102 0x910b 0x2242 0x92bc 0x90cc 0x236a 0x9476 0x9092 0x24bd 0x9630 0x9065 0x264f 0x97ea 0x9040 0x281d 0x99a4 0x901a 0x2a29 0x9b5e 0x8fed 0x2c7f 0x9d18 0x8fab 0x2f0e 0x9ed1 0x8f38 0x319b 0xa08b 0x8e71 0x33f0 0xa245 0x8d03 0x35bb 0xa3ff 0x8ad6 0x37b7 0xa5b9 0x87b6 0x3ac5 0xa773 0x8260 0x416b 0xa92d 0x78c0 0x6bc1 0xaae7 0x78c0 0x6bc1>;
		battery0_profile_t3_num = <0x64>;
		battery0_profile_t3 = <0x00 0xaab7 0x3854 0x1ba 0xa9d2 0x384f 0x374 0xa907 0x38be 0x52e 0xa84a 0x3851 0x6e8 0xa79b 0x3795 0x8a2 0xa6fa 0x36d1 0xa5c 0xa661 0x360b 0xc16 0xa5d2 0x34d4 0xdcf 0xa54a 0x3428 0xf89 0xa4c8 0x33b2 0x1143 0xa44a 0x32f7 0x12fd 0xa3d1 0x3246 0x14b7 0xa35c 0x319d 0x1671 0xa2e7 0x3106 0x182b 0xa272 0x3075 0x19e5 0xa1fe 0x2fed 0x1b9f 0xa18f 0x2f73 0x1d59 0xa120 0x2ef1 0x1f13 0xa0b9 0x2e98 0x20cd 0xa056 0x2e2b 0x2287 0x9ffb 0x2de0 0x2441 0x9f9b 0x2d8a 0x25fa 0x9f2f 0x2d1a 0x27b4 0x9eb2 0x2c93 0x296e 0x9e20 0x2bda 0x2b28 0x9d7f 0x2b11 0x2ce2 0x9cda 0x2a44 0x2e9c 0x9c3e 0x2988 0x3056 0x9baf 0x28f0 0x3210 0x9b2e 0x2877 0x33ca 0x9abb 0x2819 0x3584 0x9a55 0x27ce 0x373e 0x99f9 0x2795 0x38f8 0x99a2 0x2765 0x3ab2 0x9954 0x2747 0x3c6c 0x9908 0x271d 0x3e25 0x98c1 0x26ff 0x3fdf 0x987c 0x26db 0x4199 0x9832 0x26a6 0x4353 0x97ee 0x2687 0x450d 0x97ab 0x2665 0x46c7 0x976a 0x2641 0x4881 0x9727 0x2615 0x4a3b 0x96e8 0x25f7 0x4bf5 0x96aa 0x25e2 0x4daf 0x966e 0x25cc 0x4f69 0x9635 0x25b6 0x5123 0x95ff 0x25a2 0x52dd 0x95cb 0x259a 0x5497 0x9599 0x2599 0x5650 0x9565 0x2593 0x580a 0x9537 0x2597 0x59c4 0x950c 0x258d 0x5b7e 0x94e6 0x25ab 0x5d38 0x94bf 0x25b9 0x5ef2 0x949f 0x25e4 0x60ac 0x947f 0x2610 0x6266 0x9461 0x2643 0x6420 0x9446 0x267b 0x65da 0x942e 0x26c6 0x6794 0x9417 0x2713 0x694e 0x9402 0x2761 0x6b08 0x93eb 0x27b1 0x6cc2 0x93d5 0x2802 0x6e7b 0x93c1 0x2852 0x7035 0x93ac 0x28a2 0x71ef 0x9395 0x28f5 0x73a9 0x937f 0x294a 0x7563 0x9369 0x299e 0x771d 0x9355 0x29ff 0x78d7 0x933f 0x2a5d 0x7a91 0x9325 0x2abc 0x7c4b 0x930d 0x2b2b 0x7e05 0x92f3 0x2b98 0x7fbf 0x92d6 0x2c14 0x8179 0x92b4 0x2c7c 0x8333 0x9293 0x2cef 0x84ed 0x9271 0x2d75 0x86a6 0x924b 0x2e06 0x8860 0x9223 0x2ea5 0x8a1a 0x91f9 0x2f46 0x8bd4 0x91cc 0x2ff3 0x8d8e 0x919a 0x30b0 0x8f48 0x9165 0x3176 0x9102 0x912f 0x3252 0x92bc 0x90f7 0x333c 0x9476 0x90be 0x342e 0x9630 0x908d 0x3544 0x97ea 0x905f 0x3672 0x99a4 0x9036 0x37b4 0x9b5e 0x9007 0x3906 0x9d18 0x8fcf 0x3a6a 0x9ed1 0x8f88 0x3c03 0xa08b 0x8f10 0x3d94 0xa245 0x8e40 0x3f15 0xa3ff 0x8cf9 0x40c9 0xa5b9 0x8b13 0x42db 0xa773 0x884c 0x45f2 0xa92d 0x83b1 0x4c4c 0xaae7 0x7a34 0x6eaa>;
	};

	odm {
		led@0 {
			pwm_config = <0x00 0x00 0x00 0x00 0x00>;
			data = <0x01>;
			led_mode = <0x00>;
			compatible = "mediatek,red";
		};
		led@1 {
			pwm_config = <0x00 0x00 0x00 0x00 0x00>;
			data = <0x01>;
			led_mode = <0x00>;
			compatible = "mediatek,green";
		};
		led@2 {
			pwm_config = <0x00 0x00 0x00 0x00 0x00>;
			data = <0x01>;
			led_mode = <0x00>;
			compatible = "mediatek,blue";
		};
		led@3 {
			pwm_config = <0x00 0x00 0x00 0x00 0x00>;
			data = <0x01>;
			led_mode = <0x00>;
			compatible = "mediatek,jogball-backlight";
		};
		led@4 {
			pwm_config = <0x00 0x00 0x00 0x00 0x00>;
			data = <0x01>;
			led_mode = <0x00>;
			compatible = "mediatek,keyboard-backlight";
		};
		led@5 {
			pwm_config = <0x00 0x00 0x00 0x00 0x00>;
			data = <0x01>;
			led_mode = <0x00>;
			compatible = "mediatek,button-backlight";
		};
		led@6 {
			pwm_config = <0x00 0x01 0x00 0x00 0x00>;
			data = <0x01>;
			led_mode = <0x05>;
			compatible = "mediatek,lcd-backlight";
		};
	};

	/*
	 * CONSYS (on-die Wi-Fi/BT/GPS, A-die MT6631), vendor mt6771.dts
	 * consys@18070000 (docs/wifi-stock.md). reg as stock: CONN_MCU_CONFIG,
	 * TOP_RGU, INFRACFG_AO, SPM (the driver maps, never claims, the
	 * shared ones). Supplies at the stock voltages (vcn33 set to 3.5 V by
	 * the driver). The CONN MTCMOS is switched by the driver itself: the
	 * mainline scpsys controller does not probe on this board yet.
	 */
	consys: consys@18070000 {
		compatible = "mediatek,mt6771-consys";
		reg = <0 0x18070000 0 0x1000>,	/* CONN_MCU_CONFIG */
		      <0 0x10007000 0 0x0100>,	/* TOP_RGU */
		      <0 0x10001000 0 0x1000>,	/* INFRACFG_AO */
		      <0 0x10006000 0 0x1000>;	/* SPM */
		interrupts = <GIC_SPI 289 IRQ_TYPE_LEVEL_LOW>,
			     <GIC_SPI 291 IRQ_TYPE_LEVEL_LOW>;
		memory-region = <&consys_mem>;
		resets = <&watchdog MT8183_TOPRGU_CONN_MCU_SW_RST>;
		reset-names = "mcu";
		vcn18-supply = <&mt6358_vcn18_reg>;
		vcn28-supply = <&mt6358_vcn28_reg>;
		vcn33-supply = <&mt6358_vcn33_reg>;
		pinctrl-names = "on", "off";
		pinctrl-0 = <&consys_pins_on>;
		pinctrl-1 = <&consys_pins_off>;
	};

	/* AP <-> CONSYS MCU transport, vendor mt6771.dts btif@1100c000 */
	btif@1100c000 {
		compatible = "mediatek,btif";
		reg = <0 0x1100c000 0 0x1000>,	/* BTIF */
		      <0 0x11000a80 0 0x80>,	/* TX DMA */
		      <0 0x11000b00 0 0x80>;	/* RX DMA */
		interrupts = <GIC_SPI 114 IRQ_TYPE_LEVEL_LOW>,
			     <GIC_SPI 139 IRQ_TYPE_LEVEL_LOW>,
			     <GIC_SPI 140 IRQ_TYPE_LEVEL_LOW>;
		clocks = <&infracfg CLK_INFRA_BTIF>,
			 <&infracfg CLK_INFRA_AP_DMA>;
		clock-names = "btifc", "apdmac";
	};

	/* CONSYS Wi-Fi data path, vendor mt6771.dts wifi@180f0000 */
	wifi@180f0000 {
		compatible = "mediatek,wifi";
		reg = <0 0x180f0000 0 0x1100>,	/* WIFI-HIF */
		      <0 0x10212180 0 0x006c>,	/* CQDMA */
		      <0 0x10001000 0 0x1000>,	/* INFRACFG_AO */
		      <0 0x180e0000 0 0x0070>;	/* CONN remap config */
		interrupts = <GIC_SPI 290 IRQ_TYPE_LEVEL_LOW>,
			     <GIC_SPI 118 IRQ_TYPE_LEVEL_LOW>;
		clocks = <&infracfg CLK_INFRA_CQ_DMA>;
		clock-names = "wifi-dma";
		hardware-values = <0x00000788>,	/* HW code */
				  <0x000a5800>,	/* FW load addr */
				  <0x000a5800>;	/* FW start addr */
	};
};

/*
 * MT6358 interrupt: GPIO 182, level high. Vendor DT: main_pmic pmic_irq
 * "interrupts = <0xb6 0x04 ...>" on pio; same as mt8183-kukui.dtsi. Without
 * it the MFD fails ("IRQ index 0 not found", on glass 2026-10-25), so no
 * MT6358 regulators, and the eMMC never gets its supplies.
 */
&pmic {
	interrupts-extended = <&pio 182 IRQ_TYPE_LEVEL_HIGH>;

	/*
	 * Power-off: the vendor ATF ignores PSCI SYSTEM_OFF. mt6358-poweroff
	 * runs the vendor RTC power-down sequence and releases RG_PWRHOLD;
	 * its fallback resets through TOPRGU without "bypass power key"
	 * (docs/poweroff.md). status = "disabled" turns it off.
	 */
	mt6358_pwrc: pwrc {
		compatible = "mediatek,mt6358-pwrc";
		mediatek,toprgu = <&watchdog>;
	};

	/*
	 * Fuel gauge, measurements only (drivers/power/supply/
	 * mt6358-gauge.c, docs/power-stock.md "MT6358 fuel gauge
	 * hardware"). CAR_TUNE 930 and R_FG 10 mOhm (= no scaling) as the
	 * vendor mt6771_battery_prop.dtsi.
	 */
	mt6358_gauge: gauge {
		compatible = "mediatek,mt6358-gauge";
		io-channels = <&pmic_adc MT6358_AUXADC_BATADC>;
		io-channel-names = "batadc";
		monitored-battery = <&cosmo_battery>;
		power-supplies = <&mt6370_chg>;
		mediatek,car-tune = <930>;
		/*
		 * Usable capacity for the state of charge: 4050 mAh measured
		 * empty to full at 4.4 V on the same cell in the Gemini PDA
		 * (docs/power-stock.md "Battery level"); label 4220 mAh.
		 */
		cosmo,charge-full-microamp-hours = <4050000>;
	};
};

/*
 * PMIC keys (stock: kpd_sw_pwrkey 116 = KEY_POWER, kpd_sw_rstkey 115 =
 * KEY_VOLUMEUP on the home-key input). The driver delta uses the MT6358
 * TOP_RST_MISC layout (vendor upmu_hw.h; docs/p0-findings.md); mainline's
 * MT6397 layout cleared RG_PWRKEY_RST_EN and stranded the board twice
 * (2026-10-25). Stock kernel (hal_kpd.c, all MT6771 defconfigs
 * CONFIG_ONEKEY_REBOOT_NORMAL_MODE) sets PWRKEY_RST_EN 1, HOMEKEY_RST_EN 0;
 * live value under mainline 0x1225 (the preloader's 0x1325 is overwritten).
 * long-press-mode 1 + power-off-time-sec 1 write bits 13:12 = 1, 9 = 1,
 * 8 = 0: the same value, so the ~8 s power-key hold reset stays. Not a wake source yet (sleep wake sources are
 * separate work). bin/build-boot-img.sh checks these values.
 */
&mt6358keys {
	mediatek,long-press-mode = <1>;
	power-off-time-sec = <1>;

	power {
		/delete-property/ wakeup-source;
	};

	home {
		linux,keycodes = <KEY_VOLUMEUP>;
	};
};

/*
 * GPU power-domain supplies, as mt8183-kukui.dtsi. Missing, the whole
 * scpsys power controller fails to probe ("power-domain@2: failed to get
 * power supply", on glass 2026-10-25). The order matches stock
 * (mtk_gpufreq_core.c): VSRAM_GPU on, then VGPU, then MFG_ASYNC, MFG,
 * CORE0..2; off in reverse.
 */
&mfg_async {
	domain-supply = <&mt6358_vsram_gpu_reg>;
};

&mfg {
	domain-supply = <&mt6358_vgpu_reg>;
};

/*
 * GPU rails (GPU G2). Stock MT6771 GPU DVFS table for this unit: efuse
 * 0x11f10050 = 0x2200000c (speed bin 0x02, turbo bit 3 set) selects
 * segment 4, 300 MHz / VGPU 0.625 V up to 900 MHz / 0.900 V, VSRAM_GPU
 * 0.850 V up to 1.000 V. Stock sets VSRAM_GPU = max(VGPU + 100 mV,
 * 0.850 V); mtk-regulator-coupler does the same from these limits.
 */
&mt6358_vgpu_reg {
	regulator-min-microvolt = <625000>;
	regulator-max-microvolt = <900000>;

	regulator-coupled-with = <&mt6358_vsram_gpu_reg>;
	regulator-coupled-max-spread = <100000>;
};

&mt6358_vsram_gpu_reg {
	regulator-min-microvolt = <850000>;
	regulator-max-microvolt = <1000000>;

	regulator-coupled-with = <&mt6358_vgpu_reg>;
	regulator-coupled-max-spread = <100000>;
};

/*
 * USB device mode for bring-up networking (g_ether, CDC ECM). The SoC port
 * is the one the preloader enumerates on. High speed only for now.
 */
&ssusb {
	dr_mode = "peripheral";
	maximum-speed = "high-speed";
	/*
	 * USB 2 only: without this mtu3 also waits for the U3 MAC clock
	 * (IPPC STS1 bit 16), which never starts here (try15: STS1 0x1000d0f).
	 */
	mediatek,u3p-dis-msk = <0x1>;
	vusb33-supply = <&mt6358_vusb_reg>;
	status = "okay";
};

&mmc0 {
	/* vendor cust_mt6771_msdc.dtsi: 8-bit, 200 MHz, HS200/HS400 1.8 V, VEMC */
	status = "okay";
	pinctrl-names = "default", "state_uhs";
	pinctrl-0 = <&mmc0_pins_default>;
	pinctrl-1 = <&mmc0_pins_uhs>;
	bus-width = <8>;
	/*
	 * Start at HS200 only; HS400 (and its ds-delay tuning) comes in P2
	 * once the basic path is proven on glass.
	 */
	max-frequency = <200000000>;
	cap-mmc-highspeed;
	mmc-hs200-1_8v;
	cap-mmc-hw-reset;
	no-sdio;
	no-sd;
	vmmc-supply = <&mt6358_vemc_reg>;
	vqmmc-supply = <&mt6358_vio18_reg>;
	assigned-clocks = <&topckgen CLK_TOP_MUX_MSDC50_0>;
	assigned-clock-parents = <&topckgen CLK_TOP_MSDCPLL_CK>;
	non-removable;
};

&pio {
	aw9523_int_pins: aw9523-int-pins {
		pins-int {
			pinmux = <PINMUX_GPIO12__FUNC_GPIO12>;
			input-enable;
			bias-pull-up;
		};
	};

	/* MSDC0 pins are fixed on the die; identical to mt8183-kukui.dtsi */
	mmc0_pins_default: mmc0-default-pins {
		pins-cmd-dat {
			pinmux = <PINMUX_GPIO123__FUNC_MSDC0_DAT0>,
				 <PINMUX_GPIO128__FUNC_MSDC0_DAT1>,
				 <PINMUX_GPIO125__FUNC_MSDC0_DAT2>,
				 <PINMUX_GPIO132__FUNC_MSDC0_DAT3>,
				 <PINMUX_GPIO126__FUNC_MSDC0_DAT4>,
				 <PINMUX_GPIO129__FUNC_MSDC0_DAT5>,
				 <PINMUX_GPIO127__FUNC_MSDC0_DAT6>,
				 <PINMUX_GPIO130__FUNC_MSDC0_DAT7>,
				 <PINMUX_GPIO122__FUNC_MSDC0_CMD>;
			input-enable;
			drive-strength = <MTK_DRIVE_14mA>;
			mediatek,pull-up-adv = <01>;
		};

		pins-clk {
			pinmux = <PINMUX_GPIO124__FUNC_MSDC0_CLK>;
			drive-strength = <MTK_DRIVE_14mA>;
			mediatek,pull-down-adv = <2>;
		};

		pins-rst {
			pinmux = <PINMUX_GPIO133__FUNC_MSDC0_RSTB>;
			drive-strength = <MTK_DRIVE_14mA>;
			mediatek,pull-down-adv = <01>;
		};
	};

	mmc0_pins_uhs: mmc0-uhs-pins {
		pins-cmd-dat {
			pinmux = <PINMUX_GPIO123__FUNC_MSDC0_DAT0>,
				 <PINMUX_GPIO128__FUNC_MSDC0_DAT1>,
				 <PINMUX_GPIO125__FUNC_MSDC0_DAT2>,
				 <PINMUX_GPIO132__FUNC_MSDC0_DAT3>,
				 <PINMUX_GPIO126__FUNC_MSDC0_DAT4>,
				 <PINMUX_GPIO129__FUNC_MSDC0_DAT5>,
				 <PINMUX_GPIO127__FUNC_MSDC0_DAT6>,
				 <PINMUX_GPIO130__FUNC_MSDC0_DAT7>,
				 <PINMUX_GPIO122__FUNC_MSDC0_CMD>;
			input-enable;
			drive-strength = <MTK_DRIVE_14mA>;
			mediatek,pull-up-adv = <01>;
		};

		pins-clk {
			pinmux = <PINMUX_GPIO124__FUNC_MSDC0_CLK>;
			drive-strength = <MTK_DRIVE_14mA>;
			mediatek,pull-down-adv = <2>;
		};

		pins-ds {
			pinmux = <PINMUX_GPIO131__FUNC_MSDC0_DSL>;
			drive-strength = <MTK_DRIVE_14mA>;
			mediatek,pull-down-adv = <2>;
		};

		pins-rst {
			pinmux = <PINMUX_GPIO133__FUNC_MSDC0_RSTB>;
			drive-strength = <MTK_DRIVE_14mA>;
			mediatek,pull-down-adv = <01>;
		};
	};

	/* vendor k71v1_64_bsp.dts &apuart0: RX GPIO95, TX GPIO96 */
	uart0_pins_default: uart0-pins {
		pins-rx {
			pinmux = <PINMUX_GPIO95__FUNC_URXD0>;
			input-enable;
			bias-pull-up;
		};

		pins-tx {
			pinmux = <PINMUX_GPIO96__FUNC_UTXD0>;
		};
	};

	/*
	 * CONSYS A-die interface, stock consys_set_if_pinmux(): GPIO_MODE
	 * 0x3e0/0x3f0 set GPIO113-121 to mode 1 at power-on and back to 0
	 * at power-off. Mux only, no pin config (stock writes mode only).
	 */
	consys_pins_on: consys-on-pins {
		pins-conn {
			pinmux = <PINMUX_GPIO113__FUNC_CONN_TOP_CLK>,
				 <PINMUX_GPIO114__FUNC_CONN_TOP_DATA>,
				 <PINMUX_GPIO115__FUNC_CONN_BT_CLK>,
				 <PINMUX_GPIO116__FUNC_CONN_BT_DATA>,
				 <PINMUX_GPIO117__FUNC_CONN_WF_HB0>,
				 <PINMUX_GPIO118__FUNC_CONN_WF_HB1>,
				 <PINMUX_GPIO119__FUNC_CONN_WF_HB2>,
				 <PINMUX_GPIO120__FUNC_CONN_WB_PTA>,
				 <PINMUX_GPIO121__FUNC_CONN_HRST_B>;
		};
	};

	consys_pins_off: consys-off-pins {
		pins-conn {
			pinmux = <PINMUX_GPIO113__FUNC_GPIO113>,
				 <PINMUX_GPIO114__FUNC_GPIO114>,
				 <PINMUX_GPIO115__FUNC_GPIO115>,
				 <PINMUX_GPIO116__FUNC_GPIO116>,
				 <PINMUX_GPIO117__FUNC_GPIO117>,
				 <PINMUX_GPIO118__FUNC_GPIO118>,
				 <PINMUX_GPIO119__FUNC_GPIO119>,
				 <PINMUX_GPIO120__FUNC_GPIO120>,
				 <PINMUX_GPIO121__FUNC_GPIO121>;
		};
	};
};

/*
 * Keyboard expanders. Pin mux (SCL/SDA, pull-ups) is left as the
 * preloader sets it (GPIO50/51 = SCL3/SDA3, GPIO105/106 = SCL4/SDA4, read
 * live 2026-10-25). Both expanders are held in reset by their HWEN lines
 * (GPIO175, GPIO109: output low) until a driver releases them.
 */
&i2c4 {
	/*
	 * MT6771 i2c4 is a multi-channel controller: vendor mt6771.dts has
	 * ch_offset_default = <0x100> (AP channel) and ccu-ch-offset 0x200
	 * (camera CCU), so the AP's registers start at +0x100. Mainline
	 * i2c-mt65xx has no channel offset: the base moves instead. With the
	 * mt8183.dtsi base (0x11008000) every transfer timed out with zero
	 * controller interrupts (try23/try24).
	 */
	reg = <0 0x11008100 0 0x100>,
	      <0 0x11000100 0 0x80>;
	/*
	 * Vendor bus id 4 for the secure channel-mode restore after deep
	 * sleep (vendor i2c-mtk.c resume; without it the keyboard times out).
	 */
	mediatek,sec-mch-id = <4>;
	clock-frequency = <100000>;
	status = "okay";

	/*
	 * Built-in keyboard: 8 x 7 matrix on the AW9523 (stock: 4-005b
	 * "Integrated keyboard", vendor aw9523_key.c). Rows = P0_0..7,
	 * columns = P1_0..6; keymap = vendor key_map[] (docs/keyboard-stock.md).
	 * Stock interrupt: EINT 12 level-low, GPIO12 pull-up (dtbo fragment@59
	 * and aw9523pin). Reset: GPIO175, low = reset (aw9523_hwen_low).
	 */
	keyboard@5b {
		compatible = "awinic,aw9523-keypad";
		reg = <0x5b>;
		pinctrl-names = "default";
		pinctrl-0 = <&aw9523_int_pins>;
		interrupts-extended = <&pio 12 IRQ_TYPE_LEVEL_LOW>;
		reset-gpios = <&pio 175 GPIO_ACTIVE_LOW>;
		keypad,num-rows = <8>;
		keypad,num-columns = <7>;
		linux,keymap = <
			/* col 0 (P1_0) */
			MATRIX_KEY(0, 0, KEY_1)
			MATRIX_KEY(1, 0, KEY_U)
			MATRIX_KEY(2, 0, KEY_S)
			MATRIX_KEY(3, 0, KEY_Z)
			MATRIX_KEY(4, 0, KEY_COMMA)
			MATRIX_KEY(5, 0, KEY_APOSTROPHE)
			MATRIX_KEY(6, 0, KEY_8)
			MATRIX_KEY(7, 0, KEY_J)
			/* col 1 (P1_1) */
			MATRIX_KEY(0, 1, KEY_2)
			MATRIX_KEY(1, 1, KEY_W)
			MATRIX_KEY(2, 1, KEY_D)
			MATRIX_KEY(3, 1, KEY_C)
			MATRIX_KEY(4, 1, KEY_LEFTALT)
			MATRIX_KEY(5, 1, KEY_LEFT)
			MATRIX_KEY(6, 1, KEY_9)
			MATRIX_KEY(7, 1, KEY_K)
			/* col 2 (P1_2) */
			MATRIX_KEY(0, 2, KEY_3)
			MATRIX_KEY(1, 2, KEY_Y)
			MATRIX_KEY(2, 2, KEY_TAB)
			MATRIX_KEY(3, 2, KEY_N)
			MATRIX_KEY(4, 2, KEY_M)
			MATRIX_KEY(5, 2, KEY_DOWN)
			MATRIX_KEY(6, 2, KEY_BACKSPACE)
			MATRIX_KEY(7, 2, KEY_I)
			/* col 3 (P1_3) */
			MATRIX_KEY(0, 3, KEY_4)
			MATRIX_KEY(1, 3, KEY_T)
			MATRIX_KEY(2, 3, KEY_F)
			MATRIX_KEY(3, 3, KEY_X)
			MATRIX_KEY(4, 3, KEY_LEFTMETA)	/* Fn, as stock */
			MATRIX_KEY(5, 3, KEY_RIGHTSHIFT)
			MATRIX_KEY(6, 3, KEY_P)
			/* col 4 (P1_4) */
			MATRIX_KEY(0, 4, KEY_5)
			MATRIX_KEY(1, 4, KEY_E)
			MATRIX_KEY(2, 4, KEY_G)
			MATRIX_KEY(3, 4, KEY_V)
			MATRIX_KEY(4, 4, KEY_SPACE)
			MATRIX_KEY(5, 4, KEY_UP)
			MATRIX_KEY(6, 4, KEY_O)
			/* col 5 (P1_5) */
			MATRIX_KEY(0, 5, KEY_6)
			MATRIX_KEY(1, 5, KEY_Q)
			MATRIX_KEY(2, 5, KEY_A)
			MATRIX_KEY(3, 5, KEY_B)
			MATRIX_KEY(4, 5, KEY_DOT)
			MATRIX_KEY(5, 5, KEY_RIGHT)
			MATRIX_KEY(6, 5, KEY_ENTER)
			/* col 6 (P1_6) */
			MATRIX_KEY(0, 6, KEY_7)
			MATRIX_KEY(1, 6, KEY_R)
			MATRIX_KEY(2, 6, KEY_H)
			MATRIX_KEY(3, 6, KEY_LEFTSHIFT)
			MATRIX_KEY(4, 6, KEY_LEFTCTRL)
			MATRIX_KEY(5, 6, KEY_L)
			MATRIX_KEY(6, 6, KEY_0)
		>;
	};
};

/*
 * MT6370 sub-PMIC (charger, Type-C TCPC, backlight, ADC) on vendor i2c5 =
 * mainline &i2c11 (0x11017000, single-channel: vendor mt6771.dts has no
 * ch_offset for i2c5). Stock runs this bus at 3.4 MHz HS (live DT
 * clock-frequency 0x33e140, mediatek,hs_only); 400 kHz is used here.
 * Pin mux left as the preloader sets it (LK talks to the MT6370 on it).
 * PMU interrupt: GPIO10 = EINT 10 level-low (live /mt6370_pmu_eint).
 * docs/power-stock.md, docs/power-plan.md S1.
 *
 * Children: ADC (S1), charger (S3), general indicator sinks, and (D1) the
 * display bias (DSV) regulators and the backlight. TCPC and flashlight are
 * left out on purpose and their drivers are not built.
 */
&i2c11 {
	clock-frequency = <400000>;
	status = "okay";

	mt6370: pmic@34 {
		compatible = "mediatek,mt6370";
		reg = <0x34>;
		interrupts-extended = <&pio 10 IRQ_TYPE_LEVEL_LOW>;
		interrupt-controller;
		#interrupt-cells = <1>;

		/*
		 * Stock names sinks 1/2 green/blue; physical mapping is unknown.
		 * Sink 3 uses white only as a required binding placeholder.
		 * Labels identify channels, not observed colours or positions.
		 * Omit ISNK4 to preserve automatic charging indication.
		 */
		led-controller {
			compatible = "mediatek,mt6370-indicator";
			#address-cells = <1>;
			#size-cells = <0>;

			led@0 {
				reg = <0>;
				color = <LED_COLOR_ID_GREEN>;
				label = "cosmo:mt6370:isnk1";
				led-max-microamp = <4000>;
				default-state = "off";
			};

			led@1 {
				reg = <1>;
				color = <LED_COLOR_ID_BLUE>;
				label = "cosmo:mt6370:isnk2";
				led-max-microamp = <4000>;
				default-state = "off";
			};

			led@2 {
				reg = <2>;
				color = <LED_COLOR_ID_WHITE>;
				label = "cosmo:mt6370:isnk3";
				led-max-microamp = <4000>;
				default-state = "off";
			};
		};

		mt6370_adc: adc {
			compatible = "mediatek,mt6370-adc";
			#io-channel-cells = <1>;
		};

		/*
		 * Panel bias (stock lcm_pmic.c display_bias_enable: dsv_pos and
		 * dsv_neg at 5.4 V; boost db_vbst 5.7 V). Enabled over I2C
		 * (DB_CTRL2 bits 6/3); stock does not use the external enable
		 * pins (db_ext_en = 0, empty ENN/ENP pinctrl). LK leaves both
		 * on; the voltages below equal what LK set, so registration
		 * writes nothing. No consumer yet: regulator_ignore_unused on
		 * the cmdline keeps them on until the panel driver owns them.
		 * The readable enable bits are the bias-off check for suspend.
		 */
		regulators {
			mt6370_dsvbst: dsvbst {
				regulator-name = "mt6370-dsvbst";
				regulator-min-microvolt = <5700000>;
				regulator-max-microvolt = <5700000>;
			};

			mt6370_dsvpos: dsvpos {
				regulator-name = "mt6370-dsvpos";
				regulator-min-microvolt = <5400000>;
				regulator-max-microvolt = <5400000>;
			};

			mt6370_dsvneg: dsvneg {
				regulator-name = "mt6370-dsvneg";
				regulator-min-microvolt = <5400000>;
				regulator-max-microvolt = <5400000>;
			};
		};

		/*
		 * LCD backlight, stock limits (docs/power-stock.md "Backlight"):
		 * 4 channels, OVP 29 V and OCP 1.5 A with shutdown (equal to
		 * LK's BL_BSTCTRL 0xed), linear mode, stock cap 768 of 2048.
		 * Dimming is I2C only: no mediatek,bled-pwm-enable, so the
		 * SoC DISP_PWM input is switched off at probe (driver delta).
		 * default-brightness = LK's level (0x1a4/0x1a5 = 05/5f).
		 */
		mt6370_backlight: backlight {
			compatible = "mediatek,mt6370-backlight";
			mediatek,bled-channel-use = /bits/ 8 <0x0f>;
			mediatek,bled-ovp-shutdown;
			mediatek,bled-ovp-microvolt = <29000000>;
			mediatek,bled-ocp-shutdown;
			mediatek,bled-ocp-microamp = <1500000>;
			max-brightness = <768>;
			default-brightness = <766>;
		};

		/*
		 * Charger, run as the vendor kernel does (docs/power-stock.md):
		 * CV / IEOC / ICHG ceiling from &cosmo_battery, current by
		 * BC1.2 type, stop/resume on the battery-thermal zone (delta
		 * drivers/power/supply/mt6370-charger.c). The driver reads IBUS
		 * as the sixth io-channel, so all nine are listed in order.
		 */
		mt6370_chg: charger {
			compatible = "mediatek,mt6370-charger";
			interrupts = <68>, <48>, <6>;
			interrupt-names = "uvp_d_evt", "attach_i", "mivr";
			io-channels = <&mt6370_adc MT6370_CHAN_VBUSDIV5>,
				      <&mt6370_adc MT6370_CHAN_VBUSDIV2>,
				      <&mt6370_adc MT6370_CHAN_VSYS>,
				      <&mt6370_adc MT6370_CHAN_VBAT>,
				      <&mt6370_adc MT6370_CHAN_TS_BAT>,
				      <&mt6370_adc MT6370_CHAN_IBUS>,
				      <&mt6370_adc MT6370_CHAN_IBAT>,
				      <&mt6370_adc MT6370_CHAN_CHG_VDDP>,
				      <&mt6370_adc MT6370_CHAN_TEMP_JC>;
			monitored-battery = <&cosmo_battery>;
			/*
			 * USB2 PHY port 0 USBPHYACR6 (t-phy 0x11f40000 + COM
			 * 0x300 + 0x18), bit 23 BC11_SW_EN: vendor mu3phy
			 * mt6771 Charger_Detect_Init / Release.
			 */
			cosmo,u2phy-bc11-reg = <0x11f40318>;
		};
	};
};

&uart0 {
	pinctrl-names = "default";
	pinctrl-0 = <&uart0_pins_default>;
	status = "okay";
};

/*
 * Nothing that drives the GPU, media engines or CPU voltages probes until
 * it is brought up on purpose (AGENTS.md rule 3). The display pipeline
 * is enabled further down (display D2); the second path (OVL_2L1,
 * RDMA1, DPI) stays off.
 * The Debian rootfs carries every defconfig module, so an enabled
 * mt8183.dtsi node gets its driver loaded (try21: mediatek-drm, the
 * disp-pwm backlight, mipi-tx, panfrost and the mdp3/vcodec/jpeg probes
 * with WARN traces). The M4U and SMI sit in the display's memory path:
 * keep them out of the way of LK's running scanout too.
 */

/*
 * Display D2: mainline mediatek-drm main path OVL0 -> OVL_2L0 -> RDMA0 ->
 * COLOR -> CCORR -> AAL -> GAMMA -> DITHER -> DSI0 -> NT36672 panel.
 *
 * M4U stays as LK left it: without iommus the display scans out
 * physical buffers from CMA, as LK does.
 *
 * Sleep D1: the scpsys power controller manages the DISP domain.
 * Its probe powers on every listed domain, so AUDIO and CONN (the Wi-Fi
 * driver controls it itself) are disabled and the DISP sub-domains are
 * deleted (sub-domains are added even when disabled). Since GPU G2 it
 * also manages the MFG domains for panfrost; genpd switches them off
 * when the GPU is idle and in suspend (stock sleep checks MFG is off).
 * Powering on the already-on DISP domain only sets bits LK already set.
 * The display nodes carry DISP again, so genpd switches the domain off in
 * the noirq phase of system suspend (stock refuses to sleep with DIS on)
 * and on again before the display resumes. DSI, COLOR, CCORR, AAL, GAMMA,
 * DITHER and MUTEX have no runtime PM, so DISP never goes off at runtime.
 */
&spm {
	power-domain@MT8183_POWER_DOMAIN_AUDIO {
		status = "disabled";
	};

	power-domain@MT8183_POWER_DOMAIN_CONN {
		status = "disabled";
	};

	power-domain@MT8183_POWER_DOMAIN_DISP {
		/delete-property/ #address-cells;
		/delete-property/ #size-cells;
		/delete-node/ power-domain@MT8183_POWER_DOMAIN_CAM;
		/delete-node/ power-domain@MT8183_POWER_DOMAIN_ISP;
		/delete-node/ power-domain@MT8183_POWER_DOMAIN_VDEC;
		/delete-node/ power-domain@MT8183_POWER_DOMAIN_VENC;
		/delete-node/ power-domain@MT8183_POWER_DOMAIN_VPU_TOP;
	};
};

&mipi_tx0 {
	status = "okay";
};

&ovl0 {
	/delete-property/ iommus;
};

&ovl_2l0 {
	/delete-property/ iommus;
};

&rdma0 {
	/delete-property/ iommus;
};

/*
 * Panel: NT36672 (LK ID 0x8070), stock timings and sequences in the
 * driver (drivers/gpu/drm/panel/panel-cosmo-nt36672.c). Bias = MT6370
 * DSV over I2C. Reset = GPIO45 (stock LCM_RST pad function, MMSYS
 * LCM_RST_B 0x150); switched to GPIO mode, output high as LK leaves it,
 * so the bootloader picture stays until the first panel power-on.
 * Physical rotation 270 (docs/p0-findings.md).
 */
&dsi0 {
	#address-cells = <1>;
	#size-cells = <0>;
	status = "okay";

	panel: panel@0 {
		compatible = "planet,cosmo-nt36672";
		reg = <0>;
		pinctrl-names = "default";
		pinctrl-0 = <&panel_pins_default>;
		reset-gpios = <&pio 45 GPIO_ACTIVE_LOW>;
		vsp-supply = <&mt6370_dsvpos>;
		vsn-supply = <&mt6370_dsvneg>;
		backlight = <&mt6370_backlight>;
		rotation = <270>;

		port {
			panel_in: endpoint {
				remote-endpoint = <&dsi_out>;
			};
		};
	};
};

&dsi_out {
	remote-endpoint = <&panel_in>;
};

&pio {
	panel_pins_default: panel-pins-default {
		pins-reset {
			pinmux = <PINMUX_GPIO45__FUNC_GPIO45>;
			output-high;
		};
	};
};

&svs {
	status = "disabled";
};

&pwm0 {
	status = "disabled";
};

/*
 * GPU: Mali-G72 MP3 with panfrost. Full stock segment-4 table (G3):
 * 300 MHz / 0.625 V to 900 MHz / 0.900 V, VGPU as stock at every OPP;
 * the coupler sets VSRAM_GPU 0.850-1.000 V. Mainline mt8183 (stock
 * segment 2) has the same voltage at every shared frequency.
 */
&gpu {
	mali-supply = <&mt6358_vgpu_reg>;
	operating-points-v2 = <&cosmo_gpu_opp>;
	status = "okay";
};

/ {
	cosmo_gpu_opp: opp-table-cosmo-gpu {
		compatible = "operating-points-v2";
		opp-shared;

		opp-300000000 {
			opp-hz = /bits/ 64 <300000000>;
			opp-microvolt = <625000>;
		};
		opp-320000000 {
			opp-hz = /bits/ 64 <320000000>;
			opp-microvolt = <631250>;
		};
		opp-340000000 {
			opp-hz = /bits/ 64 <340000000>;
			opp-microvolt = <637500>;
		};
		opp-380000000 {
			opp-hz = /bits/ 64 <380000000>;
			opp-microvolt = <650000>;
		};
		opp-420000000 {
			opp-hz = /bits/ 64 <420000000>;
			opp-microvolt = <662500>;
		};
		opp-460000000 {
			opp-hz = /bits/ 64 <460000000>;
			opp-microvolt = <675000>;
		};
		opp-500000000 {
			opp-hz = /bits/ 64 <500000000>;
			opp-microvolt = <687500>;
		};
		opp-540000000 {
			opp-hz = /bits/ 64 <540000000>;
			opp-microvolt = <700000>;
		};
		opp-580000000 {
			opp-hz = /bits/ 64 <580000000>;
			opp-microvolt = <712500>;
		};
		opp-620000000 {
			opp-hz = /bits/ 64 <620000000>;
			opp-microvolt = <725000>;
		};
		opp-653000000 {
			opp-hz = /bits/ 64 <653000000>;
			opp-microvolt = <743750>;
		};
		opp-698000000 {
			opp-hz = /bits/ 64 <698000000>;
			opp-microvolt = <768750>;
		};
		opp-743000000 {
			opp-hz = /bits/ 64 <743000000>;
			opp-microvolt = <793750>;
		};
		opp-800000000 {
			opp-hz = /bits/ 64 <800000000>;
			opp-microvolt = <825000>;
		};
		opp-850000000 {
			opp-hz = /bits/ 64 <850000000>;
			opp-microvolt = <862500>;
		};
		opp-900000000 {
			opp-hz = /bits/ 64 <900000000>;
			opp-microvolt = <900000>;
		};
	};
};

&ovl_2l1 {
	status = "disabled";
};

&rdma1 {
	status = "disabled";
};

&{/soc/dma-controller0@14001000} {
	status = "disabled";
};

&{/soc/mdp3-rsz0@14003000} {
	status = "disabled";
};

&{/soc/mdp3-rsz1@14004000} {
	status = "disabled";
};

&{/soc/dma-controller@14005000} {
	status = "disabled";
};

&{/soc/mdp3-wdma@14006000} {
	status = "disabled";
};

&{/soc/mdp3-ccorr@1401c000} {
	status = "disabled";
};

&vcodec_dec {
	status = "disabled";
};

&vcodec_enc {
	status = "disabled";
};

&venc_jpg {
	status = "disabled";
};

&iommu {
	status = "disabled";
};

&smi_common {
	status = "disabled";
};

&larb0 {
	status = "disabled";
};

&larb1 {
	status = "disabled";
};

&larb2 {
	status = "disabled";
};

&larb3 {
	status = "disabled";
};

&larb4 {
	status = "disabled";
};

&larb5 {
	status = "disabled";
};

&larb6 {
	status = "disabled";
};

/*
 * Battery (same cell as the Gemini PDA; label: 3.85 V, 4220 mAh, charge
 * 4.4 V). CV 4.40 V and IEOC 150 mA as the vendor mt6370.dtsi; charge
 * current ceiling 2.0 A = what the vendor kernel actually set on a wall
 * charger (CHGCTRL7 0x4c, docs/power-stock.md). The node name "battery"
 * is taken by LK's mediatek,bat_gm30 data above.
 */
/ {
	/*
	 * Refuse system sleep while the panel bias is on (stock blanks the
	 * display and drops the bias before every suspend). Read-only.
	 */
	/*
	 * Sleep D1b: saves LK's SMI common + larb0 settings (larb0 ports 0-5
	 * MMU off) before DISP powers off in suspend, restores them after.
	 */
	smi-restore@14019000 {
		compatible = "planet,cosmo-smi-restore";
		reg = <0 0x14019000 0 0x1000>, <0 0x14017000 0 0x1000>;
		power-domains = <&spm MT8183_POWER_DOMAIN_DISP>;
	};

	sleep-guard {
		compatible = "planet,cosmo-sleep-guard";
		vpos-supply = <&mt6370_dsvpos>;
		vneg-supply = <&mt6370_dsvneg>;
	};

	cosmo_battery: cosmo-battery {
		compatible = "simple-battery";
		device-chemistry = "lithium-ion";
		charge-full-design-microamp-hours = <4220000>;
		voltage-min-design-microvolt = <3400000>;
		constant-charge-voltage-max-microvolt = <4400000>;
		constant-charge-current-max-microamp = <2000000>;
		charge-term-current-microamp = <150000>;
		/*
		 * Open-circuit voltage vs charge at 25 C from the vendor
		 * profile LK reads (battery node battery0_profile_t1, 100
		 * points, 4276 mAh to the 3.4 V vendor shutdown voltage),
		 * resampled every 5 %. Internal resistance = median of the
		 * same profile's R column (1710 x 0.1 mOhm).
		 */
		factory-internal-resistance-micro-ohms = <171000>;
		ocv-capacity-celsius = <25>;
		ocv-capacity-table-0 = <4364700 100>, <4307738 95>, <4250257 90>,
			<4193951 85>, <4139579 80>, <4085569 75>, <4041962 70>,
			<3975218 65>, <3942225 60>, <3888570 55>, <3854918 50>,
			<3829530 45>, <3809101 40>, <3792343 35>, <3777941 30>,
			<3760051 25>, <3741748 20>, <3717371 15>, <3689590 10>,
			<3677794 5>, <3400000 0>;
	};

	/*
	 * Battery NTC on MT6358 AUXADC BAT_TEMP (vendor channel 3 in
	 * pmic_auxadc.c, 10 k NTC, 24 k pull-up to VBIF28 = 2.8 V,
	 * mtk_battery_table.h Fg_Temperature_Table). The mt6359-auxadc
	 * driver reports scale = full-scale mV (3600, not 3600/4096), so
	 * its "processed" value is mV x 4096: the table is in those units
	 * (V = 2800 x R / (24000 + R), value = V x 4096). Checked: raw 891
	 * (Gemian AUXADC_ADC3) gives 27.0 C, as stock reported.
	 */
	battery_ntc: thermal-sensor-battery {
		compatible = "generic-adc-thermal";
		#thermal-sensor-cells = <0>;
		io-channels = <&pmic_adc MT6358_AUXADC_BAT_TEMP>;
		io-channel-names = "sensor-channel";
		temperature-lookup-table = <
			(-40000) 10215676
			(-35000) 9870092
			(-30000) 9464743
			(-25000) 9001485
			(-20000) 8484627
			(-15000) 7924032
			(-10000) 7330058
			(-5000) 6714236
			0 6094794
			5000 5487809
			10000 4903633
			15000 4351584
			20000 3840098
			25000 3373176
			30000 2951047
			35000 2574810
			40000 2242709
			45000 1950136
			50000 1694602
			55000 1472388
			60000 1279594
		>;
	};
};

/*
 * Battery zone: the charger stops at 55 C (driver delta); the vendor
 * kernel resets the board at 60 C (mtktsbattery-sysrst), here a critical
 * trip powers it off.
 */
&thermal_zones {
	battery-thermal {
		polling-delay = <1000>;
		polling-delay-passive = <0>;
		thermal-sensors = <&battery_ntc>;

		trips {
			battery_crit: battery-crit {
				temperature = <60000>;
				hysteresis = <2000>;
				type = "critical";
			};
		};
	};
};

/* Stock dtbo fragment@39: AW9524, i2c3 0x5b; reset in fragment@12.
 * Pin names deliberately await physical LED identification.
 */
&i2c3 {
	clock-frequency = <400000>;
	status = "okay";

	led-controller@5b {
		compatible = "awinic,aw9524-leds";
		reg = <0x5b>;
		reset-gpios = <&pio 109 GPIO_ACTIVE_LOW>;
		#address-cells = <1>;
		#size-cells = <0>;

		led@0 {
			reg = <0>;
			label = "cosmo:aw9524:p0-0";
			max-brightness = <64>;
		};

		led@1 {
			reg = <1>;
			label = "cosmo:aw9524:p0-1";
			max-brightness = <64>;
		};

		led@2 {
			reg = <2>;
			label = "cosmo:aw9524:p0-2";
			max-brightness = <64>;
		};

		led@3 {
			reg = <3>;
			label = "cosmo:aw9524:p0-3";
			max-brightness = <64>;
		};

		led@4 {
			reg = <4>;
			label = "cosmo:aw9524:p0-4";
			max-brightness = <64>;
		};

		led@5 {
			reg = <5>;
			label = "cosmo:aw9524:p0-5";
			max-brightness = <64>;
		};

		led@8 {
			reg = <8>;
			label = "cosmo:aw9524:p1-0";
			max-brightness = <64>;
		};

		led@9 {
			reg = <9>;
			label = "cosmo:aw9524:p1-1";
			max-brightness = <64>;
		};

		led@a {
			reg = <10>;
			label = "cosmo:aw9524:p1-2";
			max-brightness = <64>;
		};

		led@b {
			reg = <11>;
			label = "cosmo:aw9524:p1-3";
			max-brightness = <64>;
		};

		led@c {
			reg = <12>;
			label = "cosmo:aw9524:p1-4";
			max-brightness = <64>;
		};

		led@d {
			reg = <13>;
			label = "cosmo:aw9524:p1-5";
			max-brightness = <64>;
		};
	};
};

/*
 * Own the general PWM controller exclusively for stock PWM1 FIFO.
 * The generic PWM driver only implements old mode. No other consumer
 * uses this controller; display PWM remains disabled separately.
 */
&pwm1 {
	compatible = "planet,cosmo-kbd-backlight";
	/delete-property/ #pwm-cells;
	pinctrl-names = "default";
	pinctrl-0 = <&kbd_pwm_pins>;
	enable-gpios = <&pio 178 GPIO_ACTIVE_HIGH>;
	hdmi-detect-gpios = <&pio 54 GPIO_ACTIVE_HIGH>;
};

&pio {
	kbd_pwm_pins: kbd-pwm-pins {
		pins-pwm {
			pinmux = <PINMUX_GPIO90__FUNC_PWM_A>;
		};
	};
};

&mt6358rtc {
	/* LK and the vendor kernel count the RTC year from 1968 */
	mediatek,rtc-year-base-1968;
};

/*
 * CPU DVFS (docs/cpufreq.md). Stock frequencies (fy5tTbl, CPU level
 * V5_T); each voltage is the higher of stock's base table and the
 * EEM-adjusted value stock ran on this unit (docs/stock-reference.md).
 * Vsram follows Vproc in the MT6358 (bootloader tracking: +100 mV,
 * 0.900-1.11875 V), so only proc-supply is given.
 *
 * Full tables since step C4 (C1-C3 used only the OPPs up to 0.800 V).
 *
 * CCI: mtk-cci-devfreq first moves LK's divider /2 to /1 at the same
 * 598 MHz (kernel/delta/drivers/devfreq/mtk-cci-devfreq.c). Its
 * intermediate clock is clk26m, not mainpll: with the divider at /1,
 * mainpll would run the CCI at 1092 MHz during every change, which stock
 * pairs with 0.894-0.950 V. 26 MHz is below every OPP.
 */
/ {
	cosmo_cl0_opp: opp-table-cosmo-cluster0 {
		compatible = "operating-points-v2";
		opp-shared;

		opp-793000000 {
			opp-hz = /bits/ 64 <793000000>;
			opp-microvolt = <600000>;
			required-opps = <&cosmo_cci_273>;
		};
		opp-910000000 {
			opp-hz = /bits/ 64 <910000000>;
			opp-microvolt = <637500>;
			required-opps = <&cosmo_cci_338>;
		};
		opp-1014000000 {
			opp-hz = /bits/ 64 <1014000000>;
			opp-microvolt = <668750>;
			required-opps = <&cosmo_cci_403>;
		};
		opp-1131000000 {
			opp-hz = /bits/ 64 <1131000000>;
			opp-microvolt = <706250>;
			required-opps = <&cosmo_cci_481>;
		};
		opp-1248000000 {
			opp-hz = /bits/ 64 <1248000000>;
			opp-microvolt = <737500>;
			required-opps = <&cosmo_cci_546>;
		};
		opp-1326000000 {
			opp-hz = /bits/ 64 <1326000000>;
			opp-microvolt = <768750>;
			required-opps = <&cosmo_cci_624>;
		};
		opp-1417000000 {
			opp-hz = /bits/ 64 <1417000000>;
			opp-microvolt = <800000>;
			required-opps = <&cosmo_cci_689>;
		};
		opp-1508000000 {
			opp-hz = /bits/ 64 <1508000000>;
			opp-microvolt = <818750>;
			required-opps = <&cosmo_cci_767>;
		};
		opp-1586000000 {
			opp-hz = /bits/ 64 <1586000000>;
			opp-microvolt = <843750>;
			required-opps = <&cosmo_cci_845>;
		};
		opp-1625000000 {
			opp-hz = /bits/ 64 <1625000000>;
			opp-microvolt = <856250>;
			required-opps = <&cosmo_cci_871>;
		};
		opp-1677000000 {
			opp-hz = /bits/ 64 <1677000000>;
			opp-microvolt = <881250>;
			required-opps = <&cosmo_cci_923>;
		};
		opp-1716000000 {
			opp-hz = /bits/ 64 <1716000000>;
			opp-microvolt = <893750>;
			required-opps = <&cosmo_cci_962>;
		};
		opp-1781000000 {
			opp-hz = /bits/ 64 <1781000000>;
			opp-microvolt = <925000>;
			required-opps = <&cosmo_cci_1027>;
		};
		opp-1846000000 {
			opp-hz = /bits/ 64 <1846000000>;
			opp-microvolt = <950000>;
			required-opps = <&cosmo_cci_1092>;
		};
		opp-1924000000 {
			opp-hz = /bits/ 64 <1924000000>;
			opp-microvolt = <975000>;
			required-opps = <&cosmo_cci_1144>;
		};
		opp-1989000000 {
			opp-hz = /bits/ 64 <1989000000>;
			opp-microvolt = <1000000>;
			required-opps = <&cosmo_cci_1196>;
		};
	};

	cosmo_cl1_opp: opp-table-cosmo-cluster1 {
		compatible = "operating-points-v2";
		opp-shared;

		opp-793000000 {
			opp-hz = /bits/ 64 <793000000>;
			opp-microvolt = <706250>;
			required-opps = <&cosmo_cci_273>;
		};
		opp-910000000 {
			opp-hz = /bits/ 64 <910000000>;
			opp-microvolt = <731250>;
			required-opps = <&cosmo_cci_338>;
		};
		opp-1014000000 {
			opp-hz = /bits/ 64 <1014000000>;
			opp-microvolt = <756250>;
			required-opps = <&cosmo_cci_403>;
		};
		opp-1131000000 {
			opp-hz = /bits/ 64 <1131000000>;
			opp-microvolt = <781250>;
			required-opps = <&cosmo_cci_481>;
		};
		opp-1248000000 {
			opp-hz = /bits/ 64 <1248000000>;
			opp-microvolt = <812500>;
			required-opps = <&cosmo_cci_546>;
		};
		opp-1326000000 {
			opp-hz = /bits/ 64 <1326000000>;
			opp-microvolt = <831250>;
			required-opps = <&cosmo_cci_624>;
		};
		opp-1417000000 {
			opp-hz = /bits/ 64 <1417000000>;
			opp-microvolt = <856250>;
			required-opps = <&cosmo_cci_689>;
		};
		opp-1508000000 {
			opp-hz = /bits/ 64 <1508000000>;
			opp-microvolt = <868750>;
			required-opps = <&cosmo_cci_767>;
		};
		opp-1586000000 {
			opp-hz = /bits/ 64 <1586000000>;
			opp-microvolt = <893750>;
			required-opps = <&cosmo_cci_845>;
		};
		opp-1651000000 {
			opp-hz = /bits/ 64 <1651000000>;
			opp-microvolt = <906250>;
			required-opps = <&cosmo_cci_871>;
		};
		opp-1716000000 {
			opp-hz = /bits/ 64 <1716000000>;
			opp-microvolt = <925000>;
			required-opps = <&cosmo_cci_923>;
		};
		opp-1781000000 {
			opp-hz = /bits/ 64 <1781000000>;
			opp-microvolt = <950000>;
			required-opps = <&cosmo_cci_962>;
		};
		opp-1846000000 {
			opp-hz = /bits/ 64 <1846000000>;
			opp-microvolt = <975000>;
			required-opps = <&cosmo_cci_1027>;
		};
		opp-1924000000 {
			opp-hz = /bits/ 64 <1924000000>;
			opp-microvolt = <1000000>;
			required-opps = <&cosmo_cci_1092>;
		};
		opp-1989000000 {
			opp-hz = /bits/ 64 <1989000000>;
			opp-microvolt = <1025000>;
			required-opps = <&cosmo_cci_1144>;
		};
		opp-2106000000 {
			opp-hz = /bits/ 64 <2106000000>;
			opp-microvolt = <1050000>;
			required-opps = <&cosmo_cci_1196>;
		};
	};

	cosmo_cci_opp: opp-table-cosmo-cci {
		compatible = "operating-points-v2";
		opp-shared;

		cosmo_cci_273: opp-273000000 {
			opp-hz = /bits/ 64 <273000000>;
			opp-microvolt = <600000>;
		};
		cosmo_cci_338: opp-338000000 {
			opp-hz = /bits/ 64 <338000000>;
			opp-microvolt = <637500>;
		};
		cosmo_cci_403: opp-403000000 {
			opp-hz = /bits/ 64 <403000000>;
			opp-microvolt = <668750>;
		};
		cosmo_cci_481: opp-481000000 {
			opp-hz = /bits/ 64 <481000000>;
			opp-microvolt = <706250>;
		};
		cosmo_cci_546: opp-546000000 {
			opp-hz = /bits/ 64 <546000000>;
			opp-microvolt = <737500>;
		};
		cosmo_cci_624: opp-624000000 {
			opp-hz = /bits/ 64 <624000000>;
			opp-microvolt = <768750>;
		};
		cosmo_cci_689: opp-689000000 {
			opp-hz = /bits/ 64 <689000000>;
			opp-microvolt = <800000>;
		};
		cosmo_cci_767: opp-767000000 {
			opp-hz = /bits/ 64 <767000000>;
			opp-microvolt = <818750>;
		};
		cosmo_cci_845: opp-845000000 {
			opp-hz = /bits/ 64 <845000000>;
			opp-microvolt = <843750>;
		};
		cosmo_cci_871: opp-871000000 {
			opp-hz = /bits/ 64 <871000000>;
			opp-microvolt = <856250>;
		};
		cosmo_cci_923: opp-923000000 {
			opp-hz = /bits/ 64 <923000000>;
			opp-microvolt = <881250>;
		};
		cosmo_cci_962: opp-962000000 {
			opp-hz = /bits/ 64 <962000000>;
			opp-microvolt = <893750>;
		};
		cosmo_cci_1027: opp-1027000000 {
			opp-hz = /bits/ 64 <1027000000>;
			opp-microvolt = <925000>;
		};
		cosmo_cci_1092: opp-1092000000 {
			opp-hz = /bits/ 64 <1092000000>;
			opp-microvolt = <950000>;
		};
		cosmo_cci_1144: opp-1144000000 {
			opp-hz = /bits/ 64 <1144000000>;
			opp-microvolt = <975000>;
		};
		cosmo_cci_1196: opp-1196000000 {
			opp-hz = /bits/ 64 <1196000000>;
			opp-microvolt = <1000000>;
		};
	};
};

&cpu0 {
	operating-points-v2 = <&cosmo_cl0_opp>;
	proc-supply = <&mt6358_vproc12_reg>;
};

&cpu1 {
	operating-points-v2 = <&cosmo_cl0_opp>;
	proc-supply = <&mt6358_vproc12_reg>;
};

&cpu2 {
	operating-points-v2 = <&cosmo_cl0_opp>;
	proc-supply = <&mt6358_vproc12_reg>;
};

&cpu3 {
	operating-points-v2 = <&cosmo_cl0_opp>;
	proc-supply = <&mt6358_vproc12_reg>;
};

&cpu4 {
	operating-points-v2 = <&cosmo_cl1_opp>;
	proc-supply = <&mt6358_vproc11_reg>;
};

&cpu5 {
	operating-points-v2 = <&cosmo_cl1_opp>;
	proc-supply = <&mt6358_vproc11_reg>;
};

&cpu6 {
	operating-points-v2 = <&cosmo_cl1_opp>;
	proc-supply = <&mt6358_vproc11_reg>;
};

&cpu7 {
	operating-points-v2 = <&cosmo_cl1_opp>;
	proc-supply = <&mt6358_vproc11_reg>;
};

&cci {
	clocks = <&mcucfg CLK_MCU_BUS_SEL>, <&clk26m>;
	clock-names = "cci", "intermediate";
	operating-points-v2 = <&cosmo_cci_opp>;
	proc-supply = <&mt6358_vproc12_reg>;
};

/*
 * Vproc limits = each table's range (vproc12 = little + CCI), so a wrong
 * request can never leave stock's values for this unit.
 */
&mt6358_vproc11_reg {
	regulator-min-microvolt = <706250>;
	regulator-max-microvolt = <1050000>;
};

&mt6358_vproc12_reg {
	regulator-min-microvolt = <600000>;
	regulator-max-microvolt = <1000000>;
};

/*
 * CPU idle (I1a): core power-down only, as stock's "mcdi" state
 * (cpuidle-mt67xx_acao_v3.c: exit 300 us, residency 4500 us for CPUs
 * 0-3, 1500 us for CPUs 4-7; PSCI 0x00010001 = stock MCDI_CPU). No
 * cluster power-down yet. Needs the SSPM MCDI init that
 * cosmo-cpu-hotplug does at boot (without it a core never wakes, I1a).
 * cosmo,boot-disabled (kernel/delta drivers/cpuidle/dt_idle_states.c)
 * would start a state disabled for per-CPU tests.
 */
&{/cpus/idle-states} {
	COSMO_CPU_OFF_LL: cosmo-cpu-off-ll {
		compatible = "arm,idle-state";
		local-timer-stop;
		arm,psci-suspend-param = <0x00010001>;
		entry-latency-us = <300>;
		exit-latency-us = <300>;
		min-residency-us = <4500>;
	};

	COSMO_CPU_OFF_L: cosmo-cpu-off-l {
		compatible = "arm,idle-state";
		local-timer-stop;
		arm,psci-suspend-param = <0x00010001>;
		entry-latency-us = <300>;
		exit-latency-us = <300>;
		min-residency-us = <1500>;
	};
};

&cpu0 { cpu-idle-states = <&COSMO_CPU_OFF_LL>; };
&cpu1 { cpu-idle-states = <&COSMO_CPU_OFF_LL>; };
&cpu2 { cpu-idle-states = <&COSMO_CPU_OFF_LL>; };
&cpu3 { cpu-idle-states = <&COSMO_CPU_OFF_LL>; };
&cpu4 { cpu-idle-states = <&COSMO_CPU_OFF_L>; };
&cpu5 { cpu-idle-states = <&COSMO_CPU_OFF_L>; };
&cpu6 { cpu-idle-states = <&COSMO_CPU_OFF_L>; };
&cpu7 { cpu-idle-states = <&COSMO_CPU_OFF_L>; };

/*
 * Idle pin levels as stock (live readback of all 180 pins, stock vs this
 * kernel, docs/session-log.md 2026-10-29). Nothing else drives these pins.
 * 101/102: camera resets, stock low. 111: second speaker amp enable,
 * stock output low (was a floating input). 177: stock high, set by the
 * stock Type-C init (usb_typec.c fusb300_init).
 */
&pio {
	cam-rst0-hog {
		gpio-hog;
		gpios = <101 GPIO_ACTIVE_HIGH>;
		output-low;
		line-name = "cam-rst0-idle";
	};

	cam-rst1-hog {
		gpio-hog;
		gpios = <102 GPIO_ACTIVE_HIGH>;
		output-low;
		line-name = "cam-rst1-idle";
	};

	extamp2-hog {
		gpio-hog;
		gpios = <111 GPIO_ACTIVE_HIGH>;
		output-low;
		line-name = "extamp2-idle";
	};

	typec-177-hog {
		gpio-hog;
		gpios = <177 GPIO_ACTIVE_HIGH>;
		output-high;
		line-name = "typec-177-idle";
	};
};
